VERSION ""

NS_ :

BS_:

BU_: FUSION ZONE_FR ZONE_RR

BO_ 513 ZFR_C5000_0: 32 ZONE_FR
 SG_ ZFR_CHASSIS_LiningWearFL_Sta : 7|1@0+ (1,0) [0|1] "" FUSION
 SG_ ZFR_CHASSIS_LiningWearFR_Sta : 6|1@0+ (1,0) [0|1] "" FUSION

BO_ 514 ZRR_C5000_0: 32 ZONE_RR
 SG_ ZRR_CHASSIS_LiningWearRR_Sta : 7|1@0+ (1,0) [0|1] "" FUSION
 SG_ ZRR_CHASSIS_LiningWearRL_Sta : 6|1@0+ (1,0) [0|1] "" FUSION

BO_ 515 ZFR_C100_0: 32 ZONE_FR
 SG_ ParkBrakeSW : 7|2@0+ (1,0) [0|3] "" FUSION

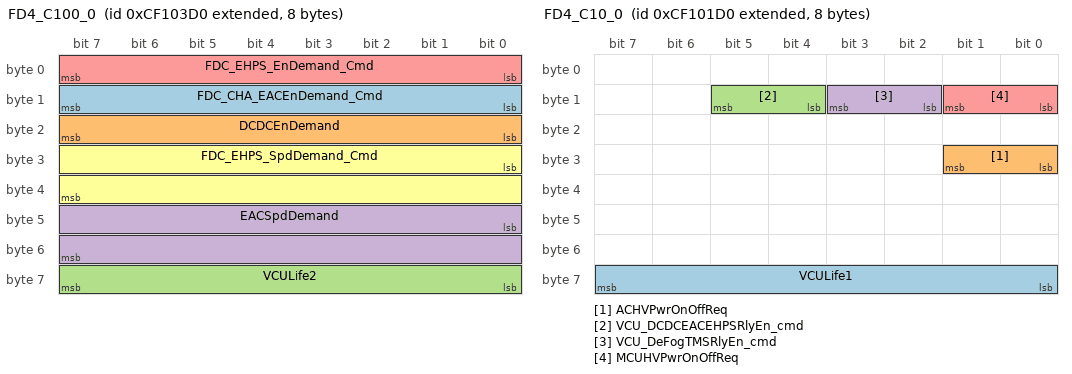
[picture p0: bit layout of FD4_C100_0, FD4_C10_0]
BO_ 2364605392 FD4_C100_0: 8 FUSION
 SG_ FDC_CHA_EACEnDemand_Cmd : 8|8@1+ (1,0) [0|255] "" ZONE_RR
 SG_ DCDCEnDemand : 16|8@1+ (1,0) [0|255] "" ZONE_RR
 SG_ VCULife2 : 56|8@1+ (1,0) [0|255] "" ZONE_RR
 SG_ EACSpdDemand : 40|16@1+ (0.5,-5000) [-5000|27767.5] "rpm" ZONE_RR
 SG_ FDC_EHPS_EnDemand_Cmd : 0|8@1+ (1,0) [0|255] "" ZONE_RR
 SG_ FDC_EHPS_SpdDemand_Cmd : 24|16@1+ (0.5,-5000) [-5000|5000] "rpm" ZONE_RR

BO_ 2566803180 ZRR_CE100_0: 8 ZONE_RR
 SG_ ZRR_BCM_AllDoor_Sta : 0|4@1+ (1,0) [0|15] "" FUSION

BO_ 517 ZFR_CE100_0: 32 ZONE_FR
 SG_ ZFR_BCM_Seatbelt_Sta : 7|1@0+ (1,0) [0|1] "" FUSION
 SG_ ZFR_BCM_Brake_Sta : 6|1@0+ (1,0) [0|1] "" FUSION
 SG_ ZFR_BCM_DVRSignalR_Sta : 5|1@0+ (1,0) [0|1] "" FUSION
 SG_ ZFR_BCM_DVRSignalL_Sta : 4|1@0+ (1,0) [0|1] "" FUSION
 SG_ ZFR_BCM_TurnBuzzer_Sta : 3|1@0+ (1,0) [0|1] "" FUSION
 SG_ ZFR_BCM_RBSDY_Sta : 2|1@0+ (1,0) [0|1] "" FUSION
 SG_ ZFR_BCM_LBSDY_Sta : 1|1@0+ (1,0) [0|1] "" FUSION
 SG_ ZFR_BCM_RBSDR_Sta : 0|1@0+ (1,0) [0|1] "" FUSION
 SG_ ZFR_BCM_LBSDR_Sta : 15|1@0+ (1,0) [0|1] "" FUSION
 SG_ ZFR_BCM_RFogLp_SW_Sta : 14|1@0+ (1,0) [0|1] "" FUSION
 SG_ ZFR_BCM_Washer_Sta : 13|1@0+ (1,0) [0|1] "" FUSION
 SG_ ZFR_BCM_WiperAS_Sta : 12|1@0+ (1,0) [0|1] "" FUSION
 SG_ ZFR_BCM_WiperL_Sta : 11|1@0+ (1,0) [0|1] "" FUSION
 SG_ ZFR_BCM_WiperH_Sta : 10|1@0+ (1,0) [0|1] "" FUSION
 SG_ ZFR_BCM_DVRMidDoor_Sta : 9|1@0+ (1,0) [0|1] "" FUSION
 SG_ ZFR_BCM_RFTurnLp_Sta : 8|1@0+ (1,0) [0|1] "" FUSION
 SG_ ZFR_BCM_LFTurnLp_Sta : 23|1@0+ (1,0) [0|1] "" FUSION
 SG_ ZFR_BCM_RDRL_Sta : 22|1@0+ (1,0) [0|1] "" FUSION
 SG_ ZFR_BCM_LDRL_Sta : 21|1@0+ (1,0) [0|1] "" FUSION
 SG_ ZFR_BCM_PLamp_Sta : 19|1@0+ (1,0) [0|1] "" FUSION
 SG_ ZFR_BCM_HBeam_Sta : 18|1@0+ (1,0) [0|1] "" FUSION
 SG_ ZFR_BCM_LBeam_Sta : 17|1@0+ (1,0) [0|1] "" FUSION
 SG_ ZFR_BCM_LightSensorV_Sta : 31|8@0+ (0.0196,0) [0|4.998] "V" FUSION
 SG_ ZFR_BCM_HBeamSW_Sta : 16|1@0+ (1,0) [0|1] "" FUSION
 SG_ ZFR_BCM_AutoLightSW_Sta : 39|1@0+ (1,0) [0|1] "" FUSION
 SG_ ZFR_BCM_PosLpSW_Sta : 38|1@0+ (1,0) [0|1] "" FUSION
 SG_ ZFR_BCM_HeadLpSW_Sta : 37|1@0+ (1,0) [0|1] "" FUSION
 SG_ ZFR_BCM_WiperHSW_Sta : 36|1@0+ (1,0) [0|1] "" FUSION
 SG_ ZFR_BCM_WiperLSW_Sta : 35|1@0+ (1,0) [0|1] "" FUSION
 SG_ ZFR_BCM_WasherSW_Sta : 34|1@0+ (1,0) [0|1] "" FUSION
 SG_ ZFR_BCM_HornSW_Sta : 33|1@0+ (1,0) [0|1] "" FUSION
 SG_ ZFR_BCM_RFTurnLpC_Sta : 47|8@0+ (0.025,0) [0|6.375] "A" FUSION
 SG_ ZFR_BCM_LFTurnLpC_Sta : 55|8@0+ (0.025,0) [0|6.375] "A" FUSION
 SG_ ZFR_BCM_BSD_Dimmer_Sta : 63|7@0+ (1,0) [0|127] "%" FUSION
 SG_ ZFR_BCM_BacklightDuty_Sta : 71|7@0+ (1,0) [0|127] "%" FUSION
 SG_ AirPressureFC2 : 79|8@0+ (8,0) [0|2008] "kPa" FUSION
 SG_ ZFR_BCM_DVRSignalReverse_Sta : 32|1@0+ (1,0) [0|1] "" FUSION

BO_ 518 ZRR_CE100_1: 32 ZONE_RR
 SG_ ZRR_BCM_EmSV_Sta : 7|1@0+ (1,0) [0|1] "" FUSION
 SG_ ZRR_BCM_MDoorAP_Sta : 6|1@0+ (1,0) [0|1] "" FUSION
 SG_ ZRR_BCM_FDoorAP_Sta : 5|1@0+ (1,0) [0|1] "" FUSION
 SG_ ZRR_BCM_MDCloseSV_Sta : 4|1@0+ (1,0) [0|1] "" FUSION
 SG_ ZRR_BCM_MDOpenSV_Sta : 3|1@0+ (1,0) [0|1] "" FUSION
 SG_ ZRR_BCM_FDCloseSV_Sta : 2|1@0+ (1,0) [0|1] "" FUSION
 SG_ ZRR_BCM_FDOpenSV_Sta : 1|1@0+ (1,0) [0|1] "" FUSION
 SG_ ZRR_BCM_ReverseBuz_Sta : 0|1@0+ (1,0) [0|1] "" FUSION
 SG_ ZRR_BCM_ReverseLp_Sta : 15|1@0+ (1,0) [0|1] "" FUSION
 SG_ ZRR_BCM_PLamp_Sta : 14|1@0+ (1,0) [0|1] "" FUSION
 SG_ ZRR_BCM_BrakeLp_Sta : 13|1@0+ (1,0) [0|1] "" FUSION
 SG_ ZRR_BCM_RFLamp_Sta : 12|1@0+ (1,0) [0|1] "" FUSION
 SG_ ZRR_BCM_TurnBuzzer_Sta : 11|1@0+ (1,0) [0|1] "" FUSION
 SG_ ZRR_BCM_RRTurnLpC_Sta : 23|8@0+ (0.025,0) [0|6.375] "A" FUSION
 SG_ ZRR_BCM_LRTurnLpC_Sta : 31|8@0+ (0.025,0) [0|6.375] "A" FUSION
 SG_ ZRR_BCM_RRTurnLp_Sta : 10|1@0+ (1,0) [0|1] "" FUSION
 SG_ ZRR_BCM_LRTurnLp_Sta : 9|1@0+ (1,0) [0|1] "" FUSION
 SG_ ZRR_BCM_CallingSW_Sta : 8|1@0+ (1,0) [0|1] "" FUSION
 SG_ ZRR_BCM_STOPSW2_Sta : 39|1@0+ (1,0) [0|1] "" FUSION
 SG_ ZRR_BCM_STOPSW_Sta : 38|1@0+ (1,0) [0|1] "" FUSION
 SG_ ZRR_BCM_SLTLp_Sta : 37|1@0+ (1,0) [0|1] "" FUSION
 SG_ ZRR_BCM_SRTLp_Sta : 36|1@0+ (1,0) [0|1] "" FUSION
 SG_ ZRR_BCM_SMKR_Sta : 35|1@0+ (1,0) [0|1] "" FUSION
 SG_ ZRR_BCM_SMKL_Sta : 34|1@0+ (1,0) [0|1] "" FUSION
 SG_ ZRR_BCM_RoomLpAmb_Sta : 33|1@0+ (1,0) [0|1] "" FUSION
 SG_ ZRR_BCM_StopLight_Sta : 32|1@0+ (1,0) [0|1] "" FUSION
 SG_ AirPressurePC3 : 47|8@0+ (8,0) [0|2000] "kPa" FUSION
 SG_ AirPressureRC1 : 55|8@0+ (8,0) [0|2008] "kPa" FUSION
 SG_ FDC_CHASSIS_VCUEACPress_Sta : 71|1@0+ (1,0) [0|1] "" FUSION
 SG_ ZRR_BCM_EmLight_Sta : 63|1@0+ (1,0) [0|1] "" FUSION

BO_ 522 zGW_CANRr1_C50_0: 32 ZONE_RR
 SG_ EAC_InvTemp_Sta : 0|8@1+ (1,-40) [-40|150] "degC" FUSION
 SG_ EHPS_InvTemp_Sta : 8|8@1+ (1,-40) [-40|150] "degC" FUSION
 SG_ DCDC_Temp_Sta : 16|8@1+ (1,-40) [-40|200] "degC" FUSION
 SG_ EAC_ErrLv_Sta : 24|3@1+ (1,0) [0|7] "" FUSION
 SG_ DCDC_OutVol_Sta : 32|16@1+ (0.1,0) [0|1000] "V" FUSION
 SG_ PDU_DCDCEACEHPSHVLoop_Sta : 27|2@1+ (1,0) [0|3] "" FUSION
 SG_ PDU_DCDCEACEHPSPreRly_Sta : 29|2@1+ (1,0) [0|3] "" FUSION
 SG_ PDU_SelfChk_Sta : 48|2@1+ (1,0) [0|3] "" FUSION
 SG_ PDU_MCUPreRly_Sta : 50|2@1+ (1,0) [0|3] "" FUSION
 SG_ PDU_MCUPosRly_Sta : 52|2@1+ (1,0) [0|3] "" FUSION
 SG_ PDU_MCUHVLoop_Sta : 54|2@1+ (1,0) [0|3] "" FUSION
 SG_ PDU_ACRly_Sta : 56|2@1+ (1,0) [0|3] "" FUSION
 SG_ PDU_DeFogTMSRly_Sta : 58|2@1+ (1,0) [0|3] "" FUSION
 SG_ PDU_DCDCEACEHPSRly_Sta : 60|2@1+ (1,0) [0|3] "" FUSION
 SG_ PDU_HVIL_Sta : 62|2@1+ (1,0) [0|3] "" FUSION
 SG_ EHPS_ErrLv_Sta : 64|3@1+ (1,0) [0|7] "" FUSION
 SG_ EHPS_En_Sta : 67|2@1+ (1,0) [0|3] "" FUSION
 SG_ EAC_En_Sta : 69|2@1+ (1,0) [0|3] "" FUSION
 SG_ DCDC_ErrLv_Sta : 72|3@1+ (1,0) [0|7] "" FUSION
 SG_ DCDC_En_Sta : 75|2@1+ (1,0) [0|3] "" FUSION
 SG_ EAC_LifeSig_Sta : 80|8@1+ (1,0) [0|255] "" FUSION
 SG_ DCDC_LifeSig_Sta : 88|8@1+ (1,0) [0|255] "" FUSION
 SG_ EHPS_MotorSpd_Sta : 96|16@1+ (0.5,-5000) [-5000|5000] "rpm" FUSION
 SG_ EHPS_LifeSig_Sta : 112|8@1+ (1,0) [0|255] "" FUSION
 SG_ PDU_LifeSig_Sta : 120|8@1+ (1,0) [0|255] "" FUSION

BO_ 2364604880 FD4_C10_0: 8 FUSION
 SG_ VCULife1 : 56|8@1+ (1,0) [0|255] "" ZONE_RR
 SG_ ACHVPwrOnOffReq : 24|2@1+ (1,0) [0|3] "" ZONE_RR
 SG_ VCU_DCDCEACEHPSRlyEn_cmd : 12|2@1+ (1,0) [0|3] "" ZONE_RR
 SG_ VCU_DeFogTMSRlyEn_cmd : 10|2@1+ (1,0) [0|3] "" ZONE_RR
 SG_ MCUHVPwrOnOffReq : 8|2@1+ (1,0) [0|3] "" ZONE_RR

BO_ 521 FD4_CE100_0: 32 FUSION
 SG_ FDC_BCM_EmSV_Cmd : 6|1@0+ (1,0) [0|1] "" ZONE_RR
 SG_ FDC_BCM_MDCloseSV_Cmd : 5|1@0+ (1,0) [0|1] "" ZONE_RR
 SG_ FDC_BCM_MDOpenSV_Cmd : 4|1@0+ (1,0) [0|1] "" ZONE_RR
 SG_ FDC_BCM_FDCloseSV_Cmd : 3|1@0+ (1,0) [0|1] "" ZONE_RR
 SG_ FDC_BCM_FDOpenSV_Cmd : 2|1@0+ (1,0) [0|1] "" ZONE_RR
 SG_ FDC_BCM_OutDoorOpenSW_Sta : 1|2@0+ (1,0) [0|3] "" ZONE_RR,ZONE_FR
 SG_ FDC_BCM_EmExitSW_Sta : 9|1@0+ (1,0) [0|1] "" ZONE_FR
 SG_ FDC_BCM_InnerBuzzer_Cmd : 8|1@0+ (1,0) [0|1] "" ZONE_FR
 SG_ FDC_BCM_InnerBuzzerMode_Sta : 23|3@0+ (1,0) [0|7] "" ZONE_FR
 SG_ FDC_BCM_CallBell_Cmd : 20|1@0+ (1,0) [0|1] "" ZONE_FR
 SG_ FDC_BCM_InnerCallBell_Cmd : 19|1@0+ (1,0) [0|1] "" ZONE_FR
 SG_ FDC_BCM_STOPBALL_Cmd : 18|1@0+ (1,0) [0|1] "" ZONE_FR
 SG_ FDC_BCM_TurnLpPattern_Sta : 17|2@0+ (1,0) [0|3] "" ZONE_FR
 SG_ FDC_BCM_RFLamp_Cmd : 31|1@0+ (1,0) [0|1] "" ZONE_RR
 SG_ FDC_BCM_Brake_Cmd : 30|1@0+ (1,0) [0|1] "" ZONE_RR,ZONE_FR
 SG_ FDC_BCM_SLTLp_Cmd : 29|1@0+ (1,0) [0|1] "" ZONE_RR
 SG_ FDC_BCM_SRTLp_Cmd : 28|1@0+ (1,0) [0|1] "" ZONE_RR
 SG_ FDC_BCM_SMKR_Cmd : 27|1@0+ (1,0) [0|1] "" ZONE_RR
 SG_ FDC_BCM_SMKL_Cmd : 26|1@0+ (1,0) [0|1] "" ZONE_RR
 SG_ FDC_BCM_RoomLpAmb_Cmd : 25|1@0+ (1,0) [0|1] "" ZONE_RR,ZONE_FR
 SG_ FDC_BCM_Stop_IND_Cmd : 24|1@0+ (1,0) [0|1] "" ZONE_RR,ZONE_FR
 SG_ FDC_BCM_BSD_Buzzer_Cmd : 39|1@0+ (1,0) [0|1] "" ZONE_RR,ZONE_FR
 SG_ FDC_BCM_RBSDY_Cmd : 38|1@0+ (1,0) [0|1] "" ZONE_FR
 SG_ FDC_BCM_RBSDR_Cmd : 37|1@0+ (1,0) [0|1] "" ZONE_FR
 SG_ FDC_BCM_LBSDY_Cmd : 36|1@0+ (1,0) [0|1] "" ZONE_FR
 SG_ FDC_BCM_LBSDR_Cmd : 35|1@0+ (1,0) [0|1] "" ZONE_FR
 SG_ FDC_BCM_Washer_Cmd : 34|1@0+ (1,0) [0|1] "" ZONE_FR
 SG_ FDC_BCM_WiperL_Cmd : 33|1@0+ (1,0) [0|1] "" ZONE_FR
 SG_ FDC_BCM_WiperH_Cmd : 32|1@0+ (1,0) [0|1] "" ZONE_FR
 SG_ FDC_BCM_RGear_Sta : 47|1@0+ (1,0) [0|1] "" ZONE_RR,ZONE_FR
 SG_ FDC_BCM_RDoor_Sta : 46|1@0+ (1,0) [0|1] "" ZONE_RR,ZONE_FR
 SG_ FDC_BCM_FDoor_Sta : 45|1@0+ (1,0) [0|1] "" ZONE_RR,ZONE_FR
 SG_ FDC_BCM_MDoor_Sta : 44|1@0+ (1,0) [0|1] "" ZONE_RR,ZONE_FR
 SG_ FDC_BCM_RDRL_Cmd : 43|1@0+ (1,0) [0|1] "" ZONE_FR
 SG_ FDC_BCM_LDRL_Cmd : 42|1@0+ (1,0) [0|1] "" ZONE_FR
 SG_ FDC_BCM_PLamp_Cmd : 41|1@0+ (1,0) [0|1] "" ZONE_RR,ZONE_FR
 SG_ FDC_BCM_HBeam_Cmd : 40|1@0+ (1,0) [0|1] "" ZONE_FR
 SG_ FDC_BCM_LBeam_Cmd : 55|1@0+ (1,0) [0|1] "" ZONE_FR
 SG_ FDC_BCM_LTurnLp_Cmd : 54|1@0+ (1,0) [0|1] "" ZONE_RR,ZONE_FR
 SG_ FDC_BCM_RTurnLp_Cmd : 53|1@0+ (1,0) [0|1] "" ZONE_RR,ZONE_FR
 SG_ FDC_BCM_DVRSignalR_Cmd : 51|1@0+ (1,0) [0|1] "" ZONE_FR
 SG_ FDC_BCM_DVRSignalL_Cmd : 52|1@0+ (1,0) [0|1] "" ZONE_FR
 SG_ VCUKeyStatus : 11|2@0+ (1,0) [0|3] "" ZONE_RR,ZONE_FR

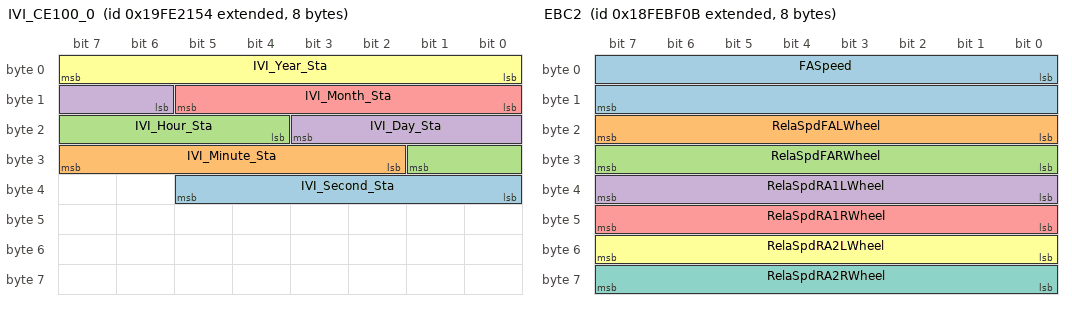
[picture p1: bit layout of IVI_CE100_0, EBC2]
BO_ 2583568724 IVI_CE100_0: 8 FUSION
 SG_ IVI_Second_Sta : 32|6@1+ (1,0) [0|60] "second" ZONE_RR,ZONE_FR
 SG_ IVI_Minute_Sta : 26|6@1+ (1,0) [0|60] "minute" ZONE_RR,ZONE_FR
 SG_ IVI_Hour_Sta : 20|6@1+ (1,0) [0|23] "hour" ZONE_RR,ZONE_FR
 SG_ IVI_Day_Sta : 14|6@1+ (1,0) [0|31] "day" ZONE_RR,ZONE_FR
 SG_ IVI_Month_Sta : 8|6@1+ (1,0) [0|13] "month" ZONE_RR,ZONE_FR
 SG_ IVI_Year_Sta : 0|8@1+ (1,2000) [2000|2127] "year" ZONE_RR,ZONE_FR

BO_ 2566831883 EBC2: 8 FUSION
 SG_ FASpeed : 0|16@1+ (0.00390625,0) [0|255.99609375] "km/h" ZONE_RR,ZONE_FR
 SG_ RelaSpdFALWheel : 16|8@1+ (0.0625,-7.8125) [-7.8125|7.8125] "km/h" Vector__XXX
 SG_ RelaSpdFARWheel : 24|8@1+ (0.0625,-7.8125) [-7.8125|7.8125] "km/h" Vector__XXX
 SG_ RelaSpdRA1LWheel : 32|8@1+ (0.0625,-7.8125) [-7.8125|7.8125] "km/h" Vector__XXX
 SG_ RelaSpdRA1RWheel : 40|8@1+ (0.0625,-7.8125) [-7.8125|7.8125] "km/h" Vector__XXX
 SG_ RelaSpdRA2LWheel : 48|8@1+ (0.0625,-7.8125) [-7.8125|7.8125] "km/h" Vector__XXX
 SG_ RelaSpdRA2RWheel : 56|8@1+ (0.0625,-7.8125) [-7.8125|7.8125] "km/h" Vector__XXX

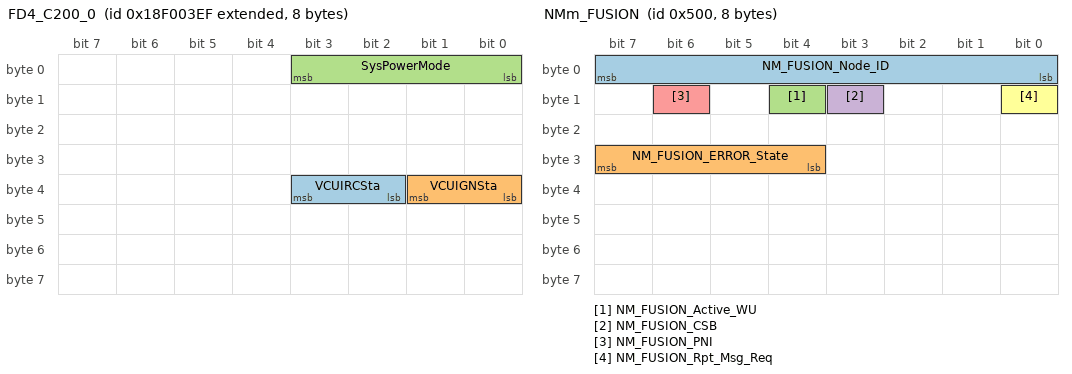
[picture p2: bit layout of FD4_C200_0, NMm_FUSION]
BO_ 2565866479 FD4_C200_0: 8 FUSION
 SG_ VCUIRCSta : 34|2@1+ (1,0) [0|3] "" ZONE_RR,ZONE_FR
 SG_ VCUIGNSta : 32|2@1+ (1,0) [0|3] "" ZONE_RR,ZONE_FR
 SG_ SysPowerMode : 0|4@1+ (1,0) [0|15] "" ZONE_RR,ZONE_FR

BO_ 2000 DiagFuncReqFT: 8 FUSION
 SG_ DiagFuncReqFT : 7|64@0+ (1,0) [0|1.8446744073709551E19] "" ZONE_RR,ZONE_FR

BO_ 1764 DiagPhysReqToZONE_RR: 64 FUSION
 SG_ DiagPhysReqToZONE_RR : 7|64@0+ (1,0) [0|1.8446744073709551E19] "" ZONE_RR

BO_ 1636 DiagRespFromZONE_RR: 64 ZONE_RR
 SG_ DiagRespFromZONE_RR : 7|64@0+ (1,0) [0|1.8446744073709551E19] "" FUSION

BO_ 1668 DiagPhysReqToZONE_FR: 64 FUSION
 SG_ DiagPhysReqToZONE_FR : 7|64@0+ (1,0) [0|1.8446744073709551E19] "" ZONE_FR

BO_ 1540 DiagRespFromZONE_FR: 64 ZONE_FR
 SG_ DiagRespFromZONE_FR : 7|64@0+ (1,0) [0|1.8446744073709551E19] "" FUSION

BO_ 528 FD4_CE100_1: 32 FUSION
 SG_ FDC_BCM_RRoomLp_Cmd : 7|7@0+ (1,0) [0|127] "%" ZONE_RR
 SG_ FDC_BCM_FRoomLp_Cmd : 39|7@0+ (1,0) [0|127] "%" ZONE_RR
 SG_ FDC_BCM_MRoomLp_Cmd : 47|7@0+ (1,0) [0|127] "%" ZONE_RR
 SG_ FDC_THCM_CoolFanReq_Cmd : 15|8@0+ (0.5,0) [0|100] "%" ZONE_RR

BO_ 1280 NMm_FUSION: 8 FUSION
 SG_ NM_FUSION_Node_ID : 7|8@0+ (1,0) [0|255] "" ZONE_RR,ZONE_FR
 SG_ NM_FUSION_ERROR_State : 31|4@0+ (1,0) [0|15] "" ZONE_RR,ZONE_FR
 SG_ NM_FUSION_Active_WU : 12|1@0+ (1,0) [0|1] "" ZONE_RR,ZONE_FR
 SG_ NM_FUSION_CSB : 11|1@0+ (1,0) [0|1] "" ZONE_RR,ZONE_FR
 SG_ NM_FUSION_PNI : 14|1@0+ (1,0) [0|1] "" ZONE_RR,ZONE_FR
 SG_ NM_FUSION_Rpt_Msg_Req : 8|1@0+ (1,0) [0|1] "" ZONE_RR,ZONE_FR

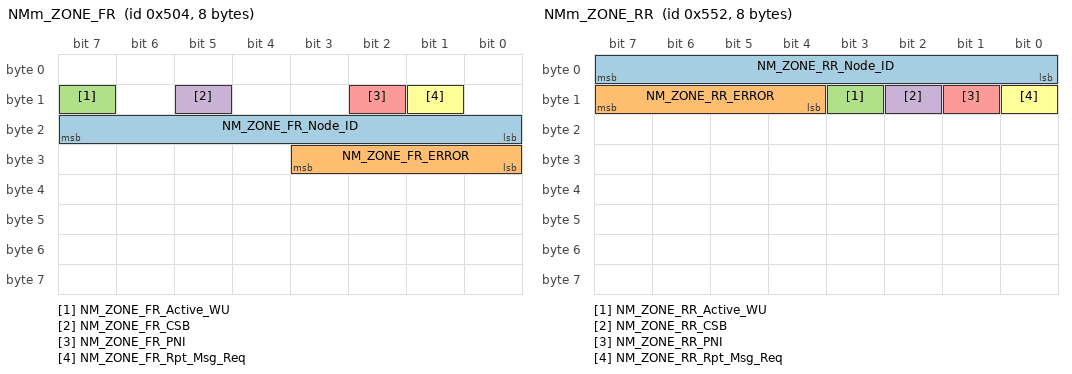
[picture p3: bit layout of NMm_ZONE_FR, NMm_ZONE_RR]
BO_ 1284 NMm_ZONE_FR: 8 ZONE_FR
 SG_ NM_ZONE_FR_Node_ID : 23|8@0+ (1,0) [0|255] "" FUSION
 SG_ NM_ZONE_FR_ERROR : 27|4@0+ (1,0) [0|15] "" FUSION
 SG_ NM_ZONE_FR_Active_WU : 15|1@0+ (1,0) [0|1] "" FUSION
 SG_ NM_ZONE_FR_CSB : 13|1@0+ (1,0) [0|1] "" FUSION
 SG_ NM_ZONE_FR_PNI : 10|1@0+ (1,0) [0|1] "" FUSION
 SG_ NM_ZONE_FR_Rpt_Msg_Req : 9|1@0+ (1,0) [0|1] "" FUSION

BO_ 1362 NMm_ZONE_RR: 8 ZONE_RR
 SG_ NM_ZONE_RR_Node_ID : 7|8@0+ (1,0) [0|255] "" FUSION
 SG_ NM_ZONE_RR_ERROR : 15|4@0+ (1,0) [0|15] "" FUSION
 SG_ NM_ZONE_RR_Active_WU : 11|1@0+ (1,0) [0|1] "" FUSION
 SG_ NM_ZONE_RR_CSB : 10|1@0+ (1,0) [0|1] "" FUSION
 SG_ NM_ZONE_RR_PNI : 9|1@0+ (1,0) [0|1] "" FUSION
 SG_ NM_ZONE_RR_Rpt_Msg_Req : 8|1@0+ (1,0) [0|1] "" FUSION

CM_ BO_ 2566803180 "FPT1_104.4_Draft，DC";
CM_ BO_ 2364604880 "FPT1_104.4_Draft，VCU_PDU_Demand_1";
CM_ BO_ 2565866479 "FPT1_104.4_Draft，VCU3";
CM_ SG_ 513 ZFR_CHASSIS_LiningWearFL_Sta "Status of FL Brake Lining";
CM_ SG_ 513 ZFR_CHASSIS_LiningWearFR_Sta "Status of FR Brake Lining";
CM_ SG_ 514 ZRR_CHASSIS_LiningWearRR_Sta "Status of RR Brake Lining";
CM_ SG_ 514 ZRR_CHASSIS_LiningWearRL_Sta "Status of RL Brake Lining";
CM_ SG_ 515 ParkBrakeSW "Parking brake switch(SPN70)";
CM_ SG_ 2364605392 FDC_CHA_EACEnDemand_Cmd "EAC enables control";
CM_ SG_ 2364605392 DCDCEnDemand "DCDC使能控制
DCDC enables control";
CM_ SG_ 2364605392 VCULife2 "VCU 生命信號
VCU Life signal";
CM_ SG_ 2364605392 EACSpdDemand "EAC電機轉速指令
EAC motor speed Demand";
CM_ SG_ 2364605392 FDC_EHPS_EnDemand_Cmd "EHPS Enable Demand";
CM_ SG_ 2364605392 FDC_EHPS_SpdDemand_Cmd "EHPS Speed Demand";
CM_ SG_ 2566803180 ZRR_BCM_AllDoor_Sta "Door Control-Status of doors(SPN 1821)
   0000b At least 1 door is open;
   0001b Closing last door;
   0010b All doors closed;
   0011b ... 1101Not defined;";
CM_ SG_ 517 ZFR_BCM_Seatbelt_Sta "Seat belt";
CM_ SG_ 517 ZFR_BCM_Brake_Sta "Output Brake Status of Zone FR";
CM_ SG_ 517 ZFR_BCM_DVRSignalR_Sta "Output DVRSignalR Status of Zone FR";
CM_ SG_ 517 ZFR_BCM_DVRSignalL_Sta "Output DVRSignalL Status of Zone FR";
CM_ SG_ 517 ZFR_BCM_TurnBuzzer_Sta "TurnBuzzer Status of Zone FR";
CM_ SG_ 517 ZFR_BCM_RBSDY_Sta "Output RBSDY Status of Zone FR";
CM_ SG_ 517 ZFR_BCM_LBSDY_Sta "Output LBSDY Status of Zone FR";
CM_ SG_ 517 ZFR_BCM_RBSDR_Sta "Output RBSDR Status of Zone FR";
CM_ SG_ 517 ZFR_BCM_LBSDR_Sta "Output LBSDR Status of Zone FR";
CM_ SG_ 517 ZFR_BCM_RFogLp_SW_Sta "Rear Fog Lamp SW";
CM_ SG_ 517 ZFR_BCM_Washer_Sta "Wiper Washer Status of Zone FR";
CM_ SG_ 517 ZFR_BCM_WiperAS_Sta "Front Wiper Park Signal";
CM_ SG_ 517 ZFR_BCM_WiperL_Sta "Wiper Low  Status of Zone FR";
CM_ SG_ 517 ZFR_BCM_WiperH_Sta "Wiper Hight Status of Zone FR";
CM_ SG_ 517 ZFR_BCM_DVRMidDoor_Sta "Output DVRMidDoor Status of Zone FR";
CM_ SG_ 517 ZFR_BCM_RFTurnLp_Sta "Right Front Turn Lamp Status of Zone FR";
CM_ SG_ 517 ZFR_BCM_LFTurnLp_Sta "Left Front Turn Lamp Status of Zone FR";
CM_ SG_ 517 ZFR_BCM_RDRL_Sta "Right DRL Lamp Status of Zone FR";
CM_ SG_ 517 ZFR_BCM_LDRL_Sta "Left DRL Lamp Status of Zone FR";
CM_ SG_ 517 ZFR_BCM_PLamp_Sta "Position Lamp Status of Zone FR";
CM_ SG_ 517 ZFR_BCM_HBeam_Sta "High Beam Lamp Status of Zone FR";
CM_ SG_ 517 ZFR_BCM_LBeam_Sta "Low Beam Lamp Status of Zone FR";
CM_ SG_ 517 ZFR_BCM_LightSensorV_Sta "Light Sensor 電壓";
CM_ SG_ 517 ZFR_BCM_HBeamSW_Sta "High Beam SW";
CM_ SG_ 517 ZFR_BCM_AutoLightSW_Sta "Auto Light Switch";
CM_ SG_ 517 ZFR_BCM_PosLpSW_Sta "Position Lamp SW";
CM_ SG_ 517 ZFR_BCM_HeadLpSW_Sta "Low Beam SW";
CM_ SG_ 517 ZFR_BCM_WiperHSW_Sta "Front Wiper Low SW";
CM_ SG_ 517 ZFR_BCM_WiperLSW_Sta "Front Wiper Low SW";
CM_ SG_ 517 ZFR_BCM_WasherSW_Sta "Front Washer SW";
CM_ SG_ 517 ZFR_BCM_HornSW_Sta "HornSW Status of Zone FR";
CM_ SG_ 517 ZFR_BCM_RFTurnLpC_Sta "Right FrontTurn Lamp Current of Zone FR";
CM_ SG_ 517 ZFR_BCM_LFTurnLpC_Sta "Left FrontTurn Lamp Current of Zone FR";
CM_ SG_ 517 ZFR_BCM_BSD_Dimmer_Sta "BSD Dimmer Status of Zone FR";
CM_ SG_ 517 ZFR_BCM_BacklightDuty_Sta "Backlight Duty Status of Zone FR";
CM_ SG_ 517 AirPressureFC2 "The pneumatic pressure in the secondary service brake circuit or reservoir, supplying the front axle";
CM_ SG_ 517 ZFR_BCM_DVRSignalReverse_Sta "Output DVRSignalReverse Status of Zone FR";
CM_ SG_ 518 ZRR_BCM_EmSV_Sta "Emergency Solenoid Valve Status of Zone RR";
CM_ SG_ 518 ZRR_BCM_MDoorAP_Sta "Middle Door Anti-pinch Status of Zone RR";
CM_ SG_ 518 ZRR_BCM_FDoorAP_Sta "Front Door Anti-pinch Status of Zone RR";
CM_ SG_ 518 ZRR_BCM_MDCloseSV_Sta "Middle Door CLose Solenoid Valve Status of Zone RR";
CM_ SG_ 518 ZRR_BCM_MDOpenSV_Sta "Middle Door Open Solenoid Valve Status of Zone RR";
CM_ SG_ 518 ZRR_BCM_FDOpenSV_Sta "Front Door Open Solenoid Valve Status of Zone RR";
CM_ SG_ 518 ZRR_BCM_ReverseBuz_Sta "Reverse_Buzzer Status of Zone RR";
CM_ SG_ 518 ZRR_BCM_ReverseLp_Sta "Reverse Lamp Status of Zone RR";
CM_ SG_ 518 ZRR_BCM_PLamp_Sta "Rear Position Lamp Status of Zone RR";
CM_ SG_ 518 ZRR_BCM_BrakeLp_Sta "Brake Lamp Status of Zone RR";
CM_ SG_ 518 ZRR_BCM_TurnBuzzer_Sta "Turn Buzzer Status of Zone RR";
CM_ SG_ 518 ZRR_BCM_LRTurnLpC_Sta "Left Rear Turn Lamp Current of Zone RR";
CM_ SG_ 518 ZRR_BCM_RRTurnLp_Sta "Right Rear Turn Lamp Status of Zone RR";
CM_ SG_ 518 ZRR_BCM_CallingSW_Sta "Calling_Switch  Status of Zone RR";
CM_ SG_ 518 ZRR_BCM_STOPSW_Sta "Stop Switch Status of Zone RR";
CM_ SG_ 518 ZRR_BCM_SLTLp_Sta "Support  Left Turn Lamp Status of Zone RR";
CM_ SG_ 518 ZRR_BCM_SRTLp_Sta "Support  Right Turn Lamp Status of Zone RR";
CM_ SG_ 518 ZRR_BCM_SMKR_Sta "Right Side Maek Lamp Status of Zone RR";
CM_ SG_ 518 ZRR_BCM_SMKL_Sta "Left Side Maek Lamp Status of Zone RR";
CM_ SG_ 518 ZRR_BCM_RoomLpAmb_Sta "Ambient Lamp Status of Zone RR";
CM_ SG_ 518 ZRR_BCM_StopLight_Sta "Zone Rr Stop light status";
CM_ SG_ 518 AirPressurePC3 "The pneumatic pressure in the circuit or reservoir for the parking brake";
CM_ SG_ 518 AirPressureRC1 "The pneumatic pressure in the primary service brake circuit or reservoir, supplying the rear axle";
CM_ SG_ 518 FDC_CHASSIS_VCUEACPress_Sta "FDC_CHASSIS_VCUEACPress_Sta";
CM_ SG_ 518 ZRR_BCM_EmLight_Sta " Emergency Light Status  of Zone_RR BCM";
CM_ SG_ 522 EAC_InvTemp_Sta "EAC溫度
The EAC  temperature";
CM_ SG_ 522 EHPS_InvTemp_Sta "EHPS溫度
The EHPS temperature";
CM_ SG_ 522 DCDC_Temp_Sta "DCDC溫度
DCDC temperature";
CM_ SG_ 522 EAC_ErrLv_Sta "EAC故障等級
EAC fault level";
CM_ SG_ 522 DCDC_OutVol_Sta "DCDC輸出電壓
DCDC output voltage";
CM_ SG_ 522 PDU_DCDCEACEHPSHVLoop_Sta "DCDC/EAC/EHPS高壓迴路狀態
DCDC/EAC/EHPS HV Loop Status";
CM_ SG_ 522 PDU_DCDCEACEHPSPreRly_Sta "DCDC/EAC/EHPS預充接觸器狀態
DCDC/EAC/EHPS Pre Rly Status";
CM_ SG_ 522 PDU_SelfChk_Sta "PDU自檢狀態
PDU Selfcheck Status";
CM_ SG_ 522 PDU_MCUPreRly_Sta "MCU預充接觸器狀態
MCU Pre Rly Status";
CM_ SG_ 522 PDU_MCUPosRly_Sta "MCU主接觸器狀態
MCU Pos Rly Status";
CM_ SG_ 522 PDU_MCUHVLoop_Sta "MCU高壓回路狀態
MCU HV Loop Status";
CM_ SG_ 522 PDU_ACRly_Sta "空調接觸器狀態
AC Rly Status";
CM_ SG_ 522 PDU_DeFogTMSRly_Sta "DeFog/TMS Relay Enable Status";
CM_ SG_ 522 PDU_DCDCEACEHPSRly_Sta "DCDC/EAC/EHPS Relay Enable  Status";
CM_ SG_ 522 PDU_HVIL_Sta "高壓互鎖狀態
HVIL_status";
CM_ SG_ 522 EHPS_ErrLv_Sta "EHPS故障等級
EHPS fault level";
CM_ SG_ 522 EHPS_En_Sta "EHPS使能狀態
EHPS enable state";
CM_ SG_ 522 EAC_En_Sta "EAC使能狀態
EAC enables the state";
CM_ SG_ 522 DCDC_ErrLv_Sta "DCDC故障等級
DCDC fault level";
CM_ SG_ 522 DCDC_En_Sta "DCDC狀態
DCDC state";
CM_ SG_ 522 EAC_LifeSig_Sta "EAC生命信號
EAC Life signal";
CM_ SG_ 522 DCDC_LifeSig_Sta "DCDC控制器生命訊號
DCDC Life signal";
CM_ SG_ 522 EHPS_MotorSpd_Sta "EHPS電機轉速
EHPS motor speed";
CM_ SG_ 522 EHPS_LifeSig_Sta "EHPS生命信號
EHPS Life signal";
CM_ SG_ 522 PDU_LifeSig_Sta "PDU生命訊號
PDU Life Signal";
CM_ SG_ 2364604880 VCULife1 "VCU生命信號
VCU vital signs";
CM_ SG_ 2364604880 ACHVPwrOnOffReq "AC高壓回路上下電請求
AC_HV_PowerOn/Off_Request
(K2&K8)";
CM_ SG_ 2364604880 VCU_DCDCEACEHPSRlyEn_cmd "DCDC/EAC/EHPS Relay enable command";
CM_ SG_ 2364604880 VCU_DeFogTMSRlyEn_cmd "DeFog/TMS Relay enable command";
CM_ SG_ 2364604880 MCUHVPwrOnOffReq "MCU高壓回路上下電請求
MCU_HV_PowerOn/Off_Request
(K1&K7)";
CM_ SG_ 521 FDC_BCM_EmSV_Cmd "緊急電磁閥做動狀態
0=Door Can_Open ,1=Door Can not Open";
CM_ SG_ 521 FDC_BCM_MDCloseSV_Cmd "後門關閉電磁閥做動狀態";
CM_ SG_ 521 FDC_BCM_MDOpenSV_Cmd "後門開啟電磁閥做動狀態";
CM_ SG_ 521 FDC_BCM_FDCloseSV_Cmd "前門關閉電磁閥做動狀態";
CM_ SG_ 521 FDC_BCM_FDOpenSV_Cmd "Front Door OpenSV Command of FDC";
CM_ SG_ 521 FDC_BCM_OutDoorOpenSW_Sta "外部車門開啟開關狀態";
CM_ SG_ 521 FDC_BCM_EmExitSW_Sta "FDC_BCM_EmExitSW_Sta";
CM_ SG_ 521 FDC_BCM_InnerBuzzer_Cmd "InnerBuzzer Command of FDC";
CM_ SG_ 521 FDC_BCM_InnerBuzzerMode_Sta "Inner Buzzer Mode ";
CM_ SG_ 521 FDC_BCM_CallBell_Cmd "CallBell Command of FDC";
CM_ SG_ 521 FDC_BCM_InnerCallBell_Cmd "InnerCallBell Command of FDC";
CM_ SG_ 521 FDC_BCM_STOPBALL_Cmd "下車鈴響鈴狀態";
CM_ SG_ 521 FDC_BCM_TurnLpPattern_Sta " Turn Lamp Pattern Status of FDC";
CM_ SG_ 521 FDC_BCM_RFLamp_Cmd "Rear Fog Indicator
後霧燈指示燈";
CM_ SG_ 521 FDC_BCM_Brake_Cmd "BCM Brake Lamp Command of FDC";
CM_ SG_ 521 FDC_BCM_SLTLp_Cmd "Suppout Turn Lamp Right";
CM_ SG_ 521 FDC_BCM_SRTLp_Cmd "Suppout Turn Lamp Left";
CM_ SG_ 521 FDC_BCM_SMKR_Cmd "右側方標示燈";
CM_ SG_ 521 FDC_BCM_SMKL_Cmd "左側方標示燈";
CM_ SG_ 521 FDC_BCM_RoomLpAmb_Cmd "Ambient Lamp Command of FDC";
CM_ SG_ 521 FDC_BCM_Stop_IND_Cmd "StopRequest";
CM_ SG_ 521 FDC_BCM_BSD_Buzzer_Cmd "BSD Buzzer Command of FDC";
CM_ SG_ 521 FDC_BCM_RBSDY_Cmd "Right BSD Yellow";
CM_ SG_ 521 FDC_BCM_RBSDR_Cmd "Right BSD Red";
CM_ SG_ 521 FDC_BCM_LBSDY_Cmd "Left BSD Yellow";
CM_ SG_ 521 FDC_BCM_LBSDR_Cmd "Left BSD Red";
CM_ SG_ 521 FDC_BCM_Washer_Cmd "Wiper Washer Command of FDC";
CM_ SG_ 521 FDC_BCM_WiperL_Cmd "Wiper Low speed Command of FDC";
CM_ SG_ 521 FDC_BCM_WiperH_Cmd "Wiper High speed Command of FDC";
CM_ SG_ 521 FDC_BCM_RGear_Sta "BCM RGear Status of FDC";
CM_ SG_ 521 FDC_BCM_RDoor_Sta "Rear Door_Sta Status of FDC";
CM_ SG_ 521 FDC_BCM_FDoor_Sta "Front Door Open Indicaor
前門開啟指示燈";
CM_ SG_ 521 FDC_BCM_MDoor_Sta "Middle Door Open Indicaor
中門開啟指示燈";
CM_ SG_ 521 FDC_BCM_RDRL_Cmd "右晝行燈狀態";
CM_ SG_ 521 FDC_BCM_LDRL_Cmd "左晝行燈狀態";
CM_ SG_ 521 FDC_BCM_PLamp_Cmd "Postion Lamp Indicator
小燈(位置燈)指示燈";
CM_ SG_ 521 FDC_BCM_HBeam_Cmd "Hi Beam Indicaotr
遠光燈指示燈";
CM_ SG_ 521 FDC_BCM_LBeam_Cmd "Low Beam Indicator
近光燈指示燈";
CM_ SG_ 521 FDC_BCM_LTurnLp_Cmd "Left Turn Indicator
左方向燈指示燈";
CM_ SG_ 521 FDC_BCM_RTurnLp_Cmd "Right Turn Indicator
右方向燈指示燈";
CM_ SG_ 521 FDC_BCM_DVRSignalR_Cmd "Turn Lamp Right Acitve";
CM_ SG_ 521 FDC_BCM_DVRSignalL_Cmd "Turn Lamp Left Acitve";
CM_ SG_ 521 VCUKeyStatus "VCU internal key status";
CM_ SG_ 2583568724 IVI_Second_Sta "IVI_GPS Satellite Time_Second";
CM_ SG_ 2583568724 IVI_Minute_Sta "IVI_GPS Satellite Time_Minute";
CM_ SG_ 2583568724 IVI_Hour_Sta "IVI_GPS Satellite Time_Hour";
CM_ SG_ 2583568724 IVI_Day_Sta "IVI_GPS Satellite Time_Day";
CM_ SG_ 2583568724 IVI_Month_Sta "IVI_GPS Satellite Time_Month";
CM_ SG_ 2583568724 IVI_Year_Sta "IVI_GPS Satellite Time_Year";
CM_ SG_ 2566831883 FASpeed "Front Axle Vehicle Speed(64256~65535=Error)";
CM_ SG_ 2566831883 RelaSpdFALWheel "The speed of the front axle, left wheel relative to the front axle speed, SPN 904.";
CM_ SG_ 2566831883 RelaSpdFARWheel "The speed of the front axle, right wheel relative to the front axle speed, SPN 904.";
CM_ SG_ 2566831883 RelaSpdRA1LWheel "The speed of the rear axle #1, left wheel relative to the front axle speed, SPN 904.";
CM_ SG_ 2566831883 RelaSpdRA1RWheel "The speed of the rear axle #1, right wheel relative to the front axle speed, SPN 904.";
CM_ SG_ 2566831883 RelaSpdRA2LWheel "The speed of the rear axle #2, left wheel relative to the front axle speed, SPN 904.";
CM_ SG_ 2566831883 RelaSpdRA2RWheel "The speed of the rear axle #2, right wheel relative to the front axle speed, SPN 904.";
CM_ SG_ 2565866479 VCUIRCSta "IRC relay status";
CM_ SG_ 2565866479 VCUIGNSta "IGN relay status";
CM_ SG_ 2565866479 SysPowerMode "HV system current power mode";
CM_ SG_ 2000 DiagFuncReqFT "Diagnostic Functional Request from Tester";
CM_ SG_ 1764 DiagPhysReqToZONE_RR "Diagnostic Physical Request to ZONE_RR";
CM_ SG_ 1636 DiagRespFromZONE_RR "Diagnostic Response from ZONE_RR";
CM_ SG_ 1668 DiagPhysReqToZONE_FR "Diagnostic Physical Request to ZONE_FR";
CM_ SG_ 1540 DiagRespFromZONE_FR "Diagnostic Response from ZONE_FR";
CM_ SG_ 528 FDC_BCM_RRoomLp_Cmd "Rear-Room-Lamp brightness Command of FD-BCM";
CM_ SG_ 528 FDC_BCM_FRoomLp_Cmd "Front-Room-Lamp brightness Command of FD-BCM";
CM_ SG_ 528 FDC_BCM_MRoomLp_Cmd "Mid-Room-Lamp brightness Command of FD-BCM";
CM_ SG_ 528 FDC_THCM_CoolFanReq_Cmd "Cooling fan duty cycle command";
CM_ SG_ 1280 NM_FUSION_Node_ID "Source Node Identifier";
CM_ SG_ 1280 NM_FUSION_ERROR_State "Defined Error states of the CAN Controller";
CM_ SG_ 1280 NM_FUSION_Active_WU "Active Wakeup Bit";
CM_ SG_ 1280 NM_FUSION_CSB "NM Coordinator Sleep Bit";
CM_ SG_ 1280 NM_FUSION_PNI "Partial Network Information Bit (PNI)";
CM_ SG_ 1280 NM_FUSION_Rpt_Msg_Req "Repeat Message Request";
CM_ SG_ 1284 NM_ZONE_FR_Node_ID "Source Node Identifier";
CM_ SG_ 1284 NM_ZONE_FR_ERROR "Defined Error states of the CAN Controller";
CM_ SG_ 1284 NM_ZONE_FR_Active_WU "Active Wakeup Bit";
CM_ SG_ 1284 NM_ZONE_FR_CSB "NM Coordinator Sleep Bit";
CM_ SG_ 1284 NM_ZONE_FR_PNI "Partial Network Information Bit (PNI)";
CM_ SG_ 1284 NM_ZONE_FR_Rpt_Msg_Req "Repeat Message Request";
CM_ SG_ 1362 NM_ZONE_RR_Node_ID "Source Node Identifier";
CM_ SG_ 1362 NM_ZONE_RR_ERROR "Defined Error states of the CAN Controller";
CM_ SG_ 1362 NM_ZONE_RR_Active_WU "Active Wakeup Bit";
CM_ SG_ 1362 NM_ZONE_RR_CSB "NM Coordinator Sleep Bit";
CM_ SG_ 1362 NM_ZONE_RR_PNI "Partial Network Information Bit (PNI)";
CM_ SG_ 1362 NM_ZONE_RR_Rpt_Msg_Req "Repeat Message Request";

BA_DEF_ SG_ "GenSigInvalidValue" HEX 0 0;
BA_DEF_ SG_ "GenSigStartValue" HEX 0 0;
BA_DEF_ SG_ "GenSigRoutingTimeoutValue_String" STRING ;
BA_DEF_ SG_ "GenSigRoutingTimeoutValue" HEX 0 0;
BA_DEF_ SG_ "GenSigSendType" ENUM "Cycle","OnWrite","OnWriteWithRepetition","OnChange","OnChangeWithRepetition","IfActive","IfActiveWithRepetition","NoSigSendType","vector_leerstring";
BA_DEF_ SG_ "SigType" ENUM "Default","Range","RangeSigned","ASCII","Discrete","Control","ReferencePGN","DTC","StringDelimiter","StringLength","StringLengthControl","MessageCounter","MessageChecksum";
BA_DEF_ SG_ "GenSigILSupport" ENUM "No","Yes";
BA_DEF_ BU_ "NodeLayerModules" STRING ;
BA_DEF_ BU_ "NmCAN" INT 1 2;
BA_DEF_ BU_ "ILUsed" ENUM "No","Yes";
BA_DEF_ BU_ "CANFD_CANFD_Gateway" ENUM "Yes","No";
BA_DEF_ BU_ "CAN_CANFD_Gateway" ENUM "Yes","No";
BA_DEF_ BU_ "CANFD_LIN_Gateway" ENUM "Yes","No";
BA_DEF_ BU_ "CAN_CAN_Gateway" ENUM "Yes","No";
BA_DEF_ "NmType" STRING ;
BA_DEF_ "VersionYear" INT 2010 2999;
BA_DEF_ "ProtocolType" STRING ;
BA_DEF_ "NmMessageCount" INT 0 255;
BA_DEF_ "NmBaseAddress" HEX 1280 1407;
BA_DEF_ "DBName" STRING ;
BA_DEF_ "BusType" STRING ;
BA_DEF_ "Baudrate" INT 0 1000000;
BA_DEF_ "Datarate" INT 0 2000000;
BA_DEF_ BO_ "GenMsgSendType" ENUM "Cycle","NoMsgSendType","IfActive","Event","CA","CE";
BA_DEF_ BO_ "GenMsgNrOfRepetition" INT 0 0;
BA_DEF_ BO_ "GenMsgILSupport" ENUM "No","Yes";
BA_DEF_ BO_ "GenMsgCycleTime" INT 0 0;
BA_DEF_ BO_ "VFrameFormat" ENUM "StandardCAN","ExtendedCAN","reserved","reserved","reserved","reserved","reserved","reserved","reserved","reserved","reserved","reserved","reserved","reserved","StandardCAN_FD","ExtendedCAN_FD";
BA_DEF_ BO_ "DoIPLogicalAddress" STRING ;
BA_DEF_ BO_ "GenMsgRequestable" INT 0 0;
BA_DEF_ BO_ "CANFD_BRS" ENUM "0","1";
BA_DEF_DEF_ "GenSigInvalidValue" 0;
BA_DEF_DEF_ "GenSigStartValue" 0;
BA_DEF_DEF_ "GenSigRoutingTimeoutValue_String" "";
BA_DEF_DEF_ "GenSigRoutingTimeoutValue" 0;
BA_DEF_DEF_ "GenSigSendType" "Cycle";
BA_DEF_DEF_ "SigType" "Default";
BA_DEF_DEF_ "GenSigILSupport" "Yes";
BA_DEF_DEF_ "NodeLayerModules" "CANoeILNLVector.dll";
BA_DEF_DEF_ "NmCAN" 2;
BA_DEF_DEF_ "ILUsed" "Yes";
BA_DEF_DEF_ "CANFD_CANFD_Gateway" "No";
BA_DEF_DEF_ "CAN_CANFD_Gateway" "No";
BA_DEF_DEF_ "CANFD_LIN_Gateway" "No";
BA_DEF_DEF_ "CAN_CAN_Gateway" "No";
BA_DEF_DEF_ "NmType" "AUTOSAR";
BA_DEF_DEF_ "VersionYear" 2024;
BA_DEF_DEF_ "ProtocolType" "CAN";
BA_DEF_DEF_ "NmMessageCount" 128;
BA_DEF_DEF_ "NmBaseAddress" 1280;
BA_DEF_DEF_ "DBName" "";
BA_DEF_DEF_ "BusType" "CAN";
BA_DEF_DEF_ "Baudrate" 500000;
BA_DEF_DEF_ "Datarate" 2000000;
BA_DEF_DEF_ "GenMsgSendType" "Cycle";
BA_DEF_DEF_ "GenMsgNrOfRepetition" 0;
BA_DEF_DEF_ "GenMsgILSupport" "Yes";
BA_DEF_DEF_ "GenMsgCycleTime" 100;
BA_DEF_DEF_ "VFrameFormat" "StandardCAN";
BA_DEF_DEF_ "DoIPLogicalAddress" "";
BA_DEF_DEF_ "GenMsgRequestable" 1;
BA_DEF_DEF_ "CANFD_BRS" "1";
BA_ "BusType" "CAN FD";
BA_ "ProtocolType" "CAN FD";
BA_ "DBName" "CAN4";
BA_ "CAN_CAN_Gateway" BU_ FUSION 0;
BA_ "CANFD_CANFD_Gateway" BU_ FUSION 0;
BA_ "CAN_CANFD_Gateway" BU_ FUSION 0;
BA_ "CAN_CAN_Gateway" BU_ ZONE_RR 0;
BA_ "CANFD_CANFD_Gateway" BU_ ZONE_RR 0;
BA_ "CAN_CANFD_Gateway" BU_ ZONE_RR 0;
BA_ "CANFD_LIN_Gateway" BU_ ZONE_RR 0;
BA_ "GenMsgCycleTime" BO_ 513 5000;
BA_ "VFrameFormat" BO_ 513 14;
BA_ "GenMsgCycleTime" BO_ 514 5000;
BA_ "VFrameFormat" BO_ 514 14;
BA_ "VFrameFormat" BO_ 515 14;
BA_ "VFrameFormat" BO_ 2364605392 1;
BA_ "GenMsgNrOfRepetition" BO_ 2566803180 1;
BA_ "VFrameFormat" BO_ 2566803180 1;
BA_ "GenMsgSendType" BO_ 2566803180 5;
BA_ "GenMsgNrOfRepetition" BO_ 517 1;
BA_ "GenMsgSendType" BO_ 517 5;
BA_ "VFrameFormat" BO_ 517 14;
BA_ "GenMsgNrOfRepetition" BO_ 518 1;
BA_ "GenMsgSendType" BO_ 518 5;
BA_ "VFrameFormat" BO_ 518 14;
BA_ "GenMsgCycleTime" BO_ 522 50;
BA_ "VFrameFormat" BO_ 522 14;
BA_ "GenMsgCycleTime" BO_ 2364604880 10;
BA_ "VFrameFormat" BO_ 2364604880 1;
BA_ "GenMsgNrOfRepetition" BO_ 521 1;
BA_ "GenMsgSendType" BO_ 521 5;
BA_ "VFrameFormat" BO_ 521 14;
BA_ "GenMsgNrOfRepetition" BO_ 2583568724 1;
BA_ "VFrameFormat" BO_ 2583568724 1;
BA_ "GenMsgSendType" BO_ 2583568724 5;
BA_ "VFrameFormat" BO_ 2566831883 1;
BA_ "GenMsgCycleTime" BO_ 2565866479 200;
BA_ "VFrameFormat" BO_ 2565866479 1;
BA_ "GenMsgCycleTime" BO_ 2000 0;
BA_ "GenMsgSendType" BO_ 2000 3;
BA_ "DoIPLogicalAddress" BO_ 2000 "0xEFFF";
BA_ "GenMsgCycleTime" BO_ 1764 0;
BA_ "GenMsgSendType" BO_ 1764 3;
BA_ "VFrameFormat" BO_ 1764 14;
BA_ "DoIPLogicalAddress" BO_ 1764 "0x06E4";
BA_ "GenMsgCycleTime" BO_ 1636 0;
BA_ "GenMsgSendType" BO_ 1636 3;
BA_ "VFrameFormat" BO_ 1636 14;
BA_ "DoIPLogicalAddress" BO_ 1636 "0x06E4";
BA_ "GenMsgCycleTime" BO_ 1668 0;
BA_ "GenMsgSendType" BO_ 1668 3;
BA_ "VFrameFormat" BO_ 1668 14;
BA_ "DoIPLogicalAddress" BO_ 1668 "0x0684";
BA_ "GenMsgCycleTime" BO_ 1540 0;
BA_ "GenMsgSendType" BO_ 1540 3;
BA_ "VFrameFormat" BO_ 1540 14;
BA_ "DoIPLogicalAddress" BO_ 1540 "0x0684";
BA_ "GenMsgNrOfRepetition" BO_ 528 1;
BA_ "GenMsgSendType" BO_ 528 5;
BA_ "VFrameFormat" BO_ 528 14;
BA_ "GenMsgCycleTime" BO_ 1280 0;
BA_ "GenMsgSendType" BO_ 1280 3;
BA_ "GenMsgCycleTime" BO_ 1284 0;
BA_ "GenMsgSendType" BO_ 1284 3;
BA_ "GenMsgCycleTime" BO_ 1362 0;
BA_ "GenMsgSendType" BO_ 1362 3;
BA_ "GenSigRoutingTimeoutValue_String" SG_ 515 ParkBrakeSW "0x3";
BA_ "GenSigRoutingTimeoutValue" SG_ 515 ParkBrakeSW 3;
BA_ "GenSigInvalidValue" SG_ 2364605392 EACSpdDemand 20001;
BA_ "GenSigStartValue" SG_ 2364605392 EACSpdDemand 10000;
BA_ "GenSigInvalidValue" SG_ 2364605392 FDC_EHPS_SpdDemand_Cmd 20000;
BA_ "GenSigSendType" SG_ 2566803180 ZRR_BCM_AllDoor_Sta 3;
BA_ "GenSigSendType" SG_ 517 ZFR_BCM_Seatbelt_Sta 3;
BA_ "GenSigRoutingTimeoutValue_String" SG_ 517 ZFR_BCM_Brake_Sta "0x0";
BA_ "GenSigSendType" SG_ 517 ZFR_BCM_Brake_Sta 3;
BA_ "GenSigRoutingTimeoutValue_String" SG_ 517 ZFR_BCM_DVRSignalR_Sta "0x0";
BA_ "GenSigSendType" SG_ 517 ZFR_BCM_DVRSignalR_Sta 3;
BA_ "GenSigRoutingTimeoutValue_String" SG_ 517 ZFR_BCM_DVRSignalL_Sta "0x0";
BA_ "GenSigSendType" SG_ 517 ZFR_BCM_DVRSignalL_Sta 3;
BA_ "GenSigRoutingTimeoutValue_String" SG_ 517 ZFR_BCM_TurnBuzzer_Sta "0x0";
BA_ "GenSigSendType" SG_ 517 ZFR_BCM_TurnBuzzer_Sta 3;
BA_ "GenSigRoutingTimeoutValue_String" SG_ 517 ZFR_BCM_RBSDY_Sta "0x0";
BA_ "GenSigSendType" SG_ 517 ZFR_BCM_RBSDY_Sta 3;
BA_ "GenSigRoutingTimeoutValue_String" SG_ 517 ZFR_BCM_LBSDY_Sta "0x0";
BA_ "GenSigSendType" SG_ 517 ZFR_BCM_LBSDY_Sta 3;
BA_ "GenSigRoutingTimeoutValue_String" SG_ 517 ZFR_BCM_RBSDR_Sta "0x0";
BA_ "GenSigSendType" SG_ 517 ZFR_BCM_RBSDR_Sta 3;
BA_ "GenSigRoutingTimeoutValue_String" SG_ 517 ZFR_BCM_LBSDR_Sta "0x0";
BA_ "GenSigSendType" SG_ 517 ZFR_BCM_LBSDR_Sta 3;
BA_ "GenSigSendType" SG_ 517 ZFR_BCM_RFogLp_SW_Sta 3;
BA_ "GenSigRoutingTimeoutValue_String" SG_ 517 ZFR_BCM_Washer_Sta "0x0";
BA_ "GenSigSendType" SG_ 517 ZFR_BCM_Washer_Sta 3;
BA_ "GenSigSendType" SG_ 517 ZFR_BCM_WiperAS_Sta 3;
BA_ "GenSigRoutingTimeoutValue_String" SG_ 517 ZFR_BCM_WiperL_Sta "0x0";
BA_ "GenSigSendType" SG_ 517 ZFR_BCM_WiperL_Sta 3;
BA_ "GenSigRoutingTimeoutValue_String" SG_ 517 ZFR_BCM_WiperH_Sta "0x0";
BA_ "GenSigSendType" SG_ 517 ZFR_BCM_WiperH_Sta 3;
BA_ "GenSigRoutingTimeoutValue_String" SG_ 517 ZFR_BCM_DVRMidDoor_Sta "0x0";
BA_ "GenSigSendType" SG_ 517 ZFR_BCM_DVRMidDoor_Sta 3;
BA_ "GenSigRoutingTimeoutValue_String" SG_ 517 ZFR_BCM_RFTurnLp_Sta "0x0";
BA_ "GenSigSendType" SG_ 517 ZFR_BCM_RFTurnLp_Sta 3;
BA_ "GenSigRoutingTimeoutValue_String" SG_ 517 ZFR_BCM_LFTurnLp_Sta "0x0";
BA_ "GenSigSendType" SG_ 517 ZFR_BCM_LFTurnLp_Sta 3;
BA_ "GenSigRoutingTimeoutValue_String" SG_ 517 ZFR_BCM_RDRL_Sta "0x0";
BA_ "GenSigSendType" SG_ 517 ZFR_BCM_RDRL_Sta 3;
BA_ "GenSigRoutingTimeoutValue_String" SG_ 517 ZFR_BCM_LDRL_Sta "0x0";
BA_ "GenSigSendType" SG_ 517 ZFR_BCM_LDRL_Sta 3;
BA_ "GenSigRoutingTimeoutValue_String" SG_ 517 ZFR_BCM_PLamp_Sta "0x0";
BA_ "GenSigSendType" SG_ 517 ZFR_BCM_PLamp_Sta 3;
BA_ "GenSigRoutingTimeoutValue_String" SG_ 517 ZFR_BCM_HBeam_Sta "0x0";
BA_ "GenSigSendType" SG_ 517 ZFR_BCM_HBeam_Sta 3;
BA_ "GenSigRoutingTimeoutValue_String" SG_ 517 ZFR_BCM_LBeam_Sta "0x0";
BA_ "GenSigSendType" SG_ 517 ZFR_BCM_LBeam_Sta 3;
BA_ "GenSigSendType" SG_ 517 ZFR_BCM_LightSensorV_Sta 3;
BA_ "GenSigSendType" SG_ 517 ZFR_BCM_HBeamSW_Sta 3;
BA_ "GenSigSendType" SG_ 517 ZFR_BCM_AutoLightSW_Sta 3;
BA_ "GenSigSendType" SG_ 517 ZFR_BCM_PosLpSW_Sta 3;
BA_ "GenSigSendType" SG_ 517 ZFR_BCM_HeadLpSW_Sta 3;
BA_ "GenSigSendType" SG_ 517 ZFR_BCM_WiperHSW_Sta 3;
BA_ "GenSigSendType" SG_ 517 ZFR_BCM_WiperLSW_Sta 3;
BA_ "GenSigSendType" SG_ 517 ZFR_BCM_WasherSW_Sta 3;
BA_ "GenSigRoutingTimeoutValue_String" SG_ 517 ZFR_BCM_HornSW_Sta "0x0";
BA_ "GenSigSendType" SG_ 517 ZFR_BCM_HornSW_Sta 3;
BA_ "GenSigInvalidValue" SG_ 517 ZFR_BCM_RFTurnLpC_Sta 255;
BA_ "GenSigStartValue" SG_ 517 ZFR_BCM_RFTurnLpC_Sta 255;
BA_ "GenSigRoutingTimeoutValue_String" SG_ 517 ZFR_BCM_RFTurnLpC_Sta "0xFF";
BA_ "GenSigRoutingTimeoutValue" SG_ 517 ZFR_BCM_RFTurnLpC_Sta 255;
BA_ "GenSigSendType" SG_ 517 ZFR_BCM_RFTurnLpC_Sta 3;
BA_ "GenSigInvalidValue" SG_ 517 ZFR_BCM_LFTurnLpC_Sta 255;
BA_ "GenSigStartValue" SG_ 517 ZFR_BCM_LFTurnLpC_Sta 255;
BA_ "GenSigRoutingTimeoutValue_String" SG_ 517 ZFR_BCM_LFTurnLpC_Sta "0xFF";
BA_ "GenSigRoutingTimeoutValue" SG_ 517 ZFR_BCM_LFTurnLpC_Sta 255;
BA_ "GenSigSendType" SG_ 517 ZFR_BCM_LFTurnLpC_Sta 3;
BA_ "GenSigInvalidValue" SG_ 517 ZFR_BCM_BSD_Dimmer_Sta 127;
BA_ "GenSigRoutingTimeoutValue_String" SG_ 517 ZFR_BCM_BSD_Dimmer_Sta "0x7F";
BA_ "GenSigRoutingTimeoutValue" SG_ 517 ZFR_BCM_BSD_Dimmer_Sta 127;
BA_ "GenSigSendType" SG_ 517 ZFR_BCM_BSD_Dimmer_Sta 3;
BA_ "GenSigInvalidValue" SG_ 517 ZFR_BCM_BacklightDuty_Sta 127;
BA_ "GenSigRoutingTimeoutValue_String" SG_ 517 ZFR_BCM_BacklightDuty_Sta "0x7F";
BA_ "GenSigRoutingTimeoutValue" SG_ 517 ZFR_BCM_BacklightDuty_Sta 127;
BA_ "GenSigRoutingTimeoutValue_String" SG_ 517 AirPressureFC2 "0xFB";
BA_ "GenSigRoutingTimeoutValue" SG_ 517 AirPressureFC2 251;
BA_ "GenSigSendType" SG_ 517 ZFR_BCM_DVRSignalReverse_Sta 3;
BA_ "GenSigRoutingTimeoutValue_String" SG_ 518 ZRR_BCM_EmSV_Sta "0x0";
BA_ "GenSigSendType" SG_ 518 ZRR_BCM_EmSV_Sta 3;
BA_ "GenSigRoutingTimeoutValue_String" SG_ 518 ZRR_BCM_MDoorAP_Sta "0x0";
BA_ "GenSigSendType" SG_ 518 ZRR_BCM_MDoorAP_Sta 3;
BA_ "GenSigRoutingTimeoutValue_String" SG_ 518 ZRR_BCM_FDoorAP_Sta "0x0";
BA_ "GenSigSendType" SG_ 518 ZRR_BCM_FDoorAP_Sta 3;
BA_ "GenSigRoutingTimeoutValue_String" SG_ 518 ZRR_BCM_MDCloseSV_Sta "0x0";
BA_ "GenSigSendType" SG_ 518 ZRR_BCM_MDCloseSV_Sta 3;
BA_ "GenSigRoutingTimeoutValue_String" SG_ 518 ZRR_BCM_MDOpenSV_Sta "0x0";
BA_ "GenSigSendType" SG_ 518 ZRR_BCM_MDOpenSV_Sta 3;
BA_ "GenSigSendType" SG_ 518 ZRR_BCM_FDCloseSV_Sta 3;
BA_ "GenSigRoutingTimeoutValue_String" SG_ 518 ZRR_BCM_FDOpenSV_Sta "0x0";
BA_ "GenSigSendType" SG_ 518 ZRR_BCM_FDOpenSV_Sta 3;
BA_ "GenSigRoutingTimeoutValue_String" SG_ 518 ZRR_BCM_ReverseBuz_Sta "0x0";
BA_ "GenSigSendType" SG_ 518 ZRR_BCM_ReverseBuz_Sta 3;
BA_ "GenSigRoutingTimeoutValue_String" SG_ 518 ZRR_BCM_ReverseLp_Sta "0x0";
BA_ "GenSigSendType" SG_ 518 ZRR_BCM_ReverseLp_Sta 3;
BA_ "GenSigRoutingTimeoutValue_String" SG_ 518 ZRR_BCM_PLamp_Sta "0x0";
BA_ "GenSigSendType" SG_ 518 ZRR_BCM_PLamp_Sta 3;
BA_ "GenSigRoutingTimeoutValue_String" SG_ 518 ZRR_BCM_BrakeLp_Sta "0x0";
BA_ "GenSigSendType" SG_ 518 ZRR_BCM_BrakeLp_Sta 3;
BA_ "GenSigSendType" SG_ 518 ZRR_BCM_RFLamp_Sta 3;
BA_ "GenSigRoutingTimeoutValue_String" SG_ 518 ZRR_BCM_TurnBuzzer_Sta "0x0";
BA_ "GenSigSendType" SG_ 518 ZRR_BCM_TurnBuzzer_Sta 3;
BA_ "GenSigRoutingTimeoutValue_String" SG_ 518 ZRR_BCM_RRTurnLpC_Sta "0xFF";
BA_ "GenSigRoutingTimeoutValue" SG_ 518 ZRR_BCM_RRTurnLpC_Sta 255;
BA_ "GenSigSendType" SG_ 518 ZRR_BCM_RRTurnLpC_Sta 3;
BA_ "GenSigRoutingTimeoutValue_String" SG_ 518 ZRR_BCM_LRTurnLpC_Sta "0xFF";
BA_ "GenSigRoutingTimeoutValue" SG_ 518 ZRR_BCM_LRTurnLpC_Sta 255;
BA_ "GenSigSendType" SG_ 518 ZRR_BCM_LRTurnLpC_Sta 3;
BA_ "GenSigRoutingTimeoutValue_String" SG_ 518 ZRR_BCM_RRTurnLp_Sta "0x0";
BA_ "GenSigSendType" SG_ 518 ZRR_BCM_RRTurnLp_Sta 3;
BA_ "GenSigSendType" SG_ 518 ZRR_BCM_LRTurnLp_Sta 3;
BA_ "GenSigRoutingTimeoutValue_String" SG_ 518 ZRR_BCM_CallingSW_Sta "0x0";
BA_ "GenSigSendType" SG_ 518 ZRR_BCM_CallingSW_Sta 3;
BA_ "GenSigSendType" SG_ 518 ZRR_BCM_STOPSW2_Sta 3;
BA_ "GenSigRoutingTimeoutValue_String" SG_ 518 ZRR_BCM_STOPSW_Sta "0x0";
BA_ "GenSigSendType" SG_ 518 ZRR_BCM_STOPSW_Sta 3;
BA_ "GenSigRoutingTimeoutValue_String" SG_ 518 ZRR_BCM_SLTLp_Sta "0x0";
BA_ "GenSigSendType" SG_ 518 ZRR_BCM_SLTLp_Sta 3;
BA_ "GenSigRoutingTimeoutValue_String" SG_ 518 ZRR_BCM_SRTLp_Sta "0x0";
BA_ "GenSigSendType" SG_ 518 ZRR_BCM_SRTLp_Sta 3;
BA_ "GenSigRoutingTimeoutValue_String" SG_ 518 ZRR_BCM_SMKR_Sta "0x0";
BA_ "GenSigSendType" SG_ 518 ZRR_BCM_SMKR_Sta 3;
BA_ "GenSigRoutingTimeoutValue_String" SG_ 518 ZRR_BCM_SMKL_Sta "0x0";
BA_ "GenSigSendType" SG_ 518 ZRR_BCM_SMKL_Sta 3;
BA_ "GenSigRoutingTimeoutValue_String" SG_ 518 ZRR_BCM_RoomLpAmb_Sta "0x0";
BA_ "GenSigSendType" SG_ 518 ZRR_BCM_RoomLpAmb_Sta 3;
BA_ "GenSigRoutingTimeoutValue_String" SG_ 518 ZRR_BCM_StopLight_Sta "0x0";
BA_ "GenSigSendType" SG_ 518 ZRR_BCM_StopLight_Sta 3;
BA_ "GenSigRoutingTimeoutValue_String" SG_ 518 AirPressureRC1 "0xFB";
BA_ "GenSigRoutingTimeoutValue" SG_ 518 AirPressureRC1 251;
BA_ "GenSigRoutingTimeoutValue_String" SG_ 522 EAC_ErrLv_Sta "0x5";
BA_ "GenSigRoutingTimeoutValue" SG_ 522 EAC_ErrLv_Sta 5;
BA_ "GenSigRoutingTimeoutValue_String" SG_ 522 PDU_SelfChk_Sta "0x3";
BA_ "GenSigRoutingTimeoutValue" SG_ 522 PDU_SelfChk_Sta 3;
BA_ "GenSigRoutingTimeoutValue_String" SG_ 522 EHPS_ErrLv_Sta "0x5";
BA_ "GenSigRoutingTimeoutValue" SG_ 522 EHPS_ErrLv_Sta 5;
BA_ "GenSigRoutingTimeoutValue_String" SG_ 522 DCDC_ErrLv_Sta "0x5";
BA_ "GenSigRoutingTimeoutValue" SG_ 522 DCDC_ErrLv_Sta 5;
BA_ "GenSigRoutingTimeoutValue_String" SG_ 2364604880 ACHVPwrOnOffReq "0x0";
BA_ "GenSigRoutingTimeoutValue_String" SG_ 2364604880 VCU_DCDCEACEHPSRlyEn_cmd "0x3";
BA_ "GenSigRoutingTimeoutValue" SG_ 2364604880 VCU_DCDCEACEHPSRlyEn_cmd 3;
BA_ "GenSigRoutingTimeoutValue_String" SG_ 2364604880 VCU_DeFogTMSRlyEn_cmd "0x3";
BA_ "GenSigRoutingTimeoutValue" SG_ 2364604880 VCU_DeFogTMSRlyEn_cmd 3;
BA_ "GenSigRoutingTimeoutValue_String" SG_ 2364604880 MCUHVPwrOnOffReq "0x0";
BA_ "GenSigSendType" SG_ 521 FDC_BCM_EmSV_Cmd 3;
BA_ "GenSigSendType" SG_ 521 FDC_BCM_MDCloseSV_Cmd 3;
BA_ "GenSigSendType" SG_ 521 FDC_BCM_MDOpenSV_Cmd 3;
BA_ "GenSigSendType" SG_ 521 FDC_BCM_FDCloseSV_Cmd 3;
BA_ "GenSigSendType" SG_ 521 FDC_BCM_FDOpenSV_Cmd 3;
BA_ "GenSigSendType" SG_ 521 FDC_BCM_OutDoorOpenSW_Sta 3;
BA_ "GenSigRoutingTimeoutValue_String" SG_ 521 FDC_BCM_EmExitSW_Sta "0x0";
BA_ "GenSigSendType" SG_ 521 FDC_BCM_EmExitSW_Sta 3;
BA_ "GenSigRoutingTimeoutValue_String" SG_ 521 FDC_BCM_InnerBuzzer_Cmd "0x0";
BA_ "GenSigSendType" SG_ 521 FDC_BCM_InnerBuzzer_Cmd 3;
BA_ "GenSigSendType" SG_ 521 FDC_BCM_InnerBuzzerMode_Sta 3;
BA_ "GenSigRoutingTimeoutValue_String" SG_ 521 FDC_BCM_CallBell_Cmd "0x0";
BA_ "GenSigSendType" SG_ 521 FDC_BCM_CallBell_Cmd 3;
BA_ "GenSigRoutingTimeoutValue_String" SG_ 521 FDC_BCM_InnerCallBell_Cmd "0x0";
BA_ "GenSigSendType" SG_ 521 FDC_BCM_InnerCallBell_Cmd 3;
BA_ "GenSigSendType" SG_ 521 FDC_BCM_STOPBALL_Cmd 3;
BA_ "GenSigRoutingTimeoutValue_String" SG_ 521 FDC_BCM_TurnLpPattern_Sta "0x0";
BA_ "GenSigSendType" SG_ 521 FDC_BCM_TurnLpPattern_Sta 3;
BA_ "GenSigSendType" SG_ 521 FDC_BCM_RFLamp_Cmd 3;
BA_ "GenSigRoutingTimeoutValue_String" SG_ 521 FDC_BCM_Brake_Cmd "0x0";
BA_ "GenSigSendType" SG_ 521 FDC_BCM_Brake_Cmd 3;
BA_ "GenSigSendType" SG_ 521 FDC_BCM_SLTLp_Cmd 3;
BA_ "GenSigSendType" SG_ 521 FDC_BCM_SRTLp_Cmd 3;
BA_ "GenSigSendType" SG_ 521 FDC_BCM_SMKR_Cmd 3;
BA_ "GenSigSendType" SG_ 521 FDC_BCM_SMKL_Cmd 3;
BA_ "GenSigRoutingTimeoutValue_String" SG_ 521 FDC_BCM_RoomLpAmb_Cmd "0x0";
BA_ "GenSigSendType" SG_ 521 FDC_BCM_RoomLpAmb_Cmd 3;
BA_ "GenSigSendType" SG_ 521 FDC_BCM_Stop_IND_Cmd 3;
BA_ "GenSigRoutingTimeoutValue_String" SG_ 521 FDC_BCM_BSD_Buzzer_Cmd "0x0";
BA_ "GenSigSendType" SG_ 521 FDC_BCM_BSD_Buzzer_Cmd 3;
BA_ "GenSigSendType" SG_ 521 FDC_BCM_RBSDY_Cmd 3;
BA_ "GenSigSendType" SG_ 521 FDC_BCM_RBSDR_Cmd 3;
BA_ "GenSigSendType" SG_ 521 FDC_BCM_LBSDY_Cmd 3;
BA_ "GenSigSendType" SG_ 521 FDC_BCM_LBSDR_Cmd 3;
BA_ "GenSigRoutingTimeoutValue_String" SG_ 521 FDC_BCM_Washer_Cmd "0x0";
BA_ "GenSigSendType" SG_ 521 FDC_BCM_Washer_Cmd 3;
BA_ "GenSigRoutingTimeoutValue_String" SG_ 521 FDC_BCM_WiperL_Cmd "0x0";
BA_ "GenSigSendType" SG_ 521 FDC_BCM_WiperL_Cmd 3;
BA_ "GenSigRoutingTimeoutValue_String" SG_ 521 FDC_BCM_WiperH_Cmd "0x0";
BA_ "GenSigSendType" SG_ 521 FDC_BCM_WiperH_Cmd 3;
BA_ "GenSigRoutingTimeoutValue_String" SG_ 521 FDC_BCM_RGear_Sta "0x0";
BA_ "GenSigSendType" SG_ 521 FDC_BCM_RGear_Sta 3;
BA_ "GenSigRoutingTimeoutValue_String" SG_ 521 FDC_BCM_RDoor_Sta "0x0";
BA_ "GenSigSendType" SG_ 521 FDC_BCM_RDoor_Sta 3;
BA_ "GenSigSendType" SG_ 521 FDC_BCM_FDoor_Sta 3;
BA_ "GenSigSendType" SG_ 521 FDC_BCM_MDoor_Sta 3;
BA_ "GenSigSendType" SG_ 521 FDC_BCM_RDRL_Cmd 3;
BA_ "GenSigSendType" SG_ 521 FDC_BCM_LDRL_Cmd 3;
BA_ "GenSigSendType" SG_ 521 FDC_BCM_PLamp_Cmd 3;
BA_ "GenSigSendType" SG_ 521 FDC_BCM_HBeam_Cmd 3;
BA_ "GenSigSendType" SG_ 521 FDC_BCM_LBeam_Cmd 3;
BA_ "GenSigRoutingTimeoutValue_String" SG_ 521 VCUKeyStatus "0x3";
BA_ "GenSigRoutingTimeoutValue" SG_ 521 VCUKeyStatus 3;
BA_ "GenSigInvalidValue" SG_ 2583568724 IVI_Second_Sta 60;
BA_ "GenSigSendType" SG_ 2583568724 IVI_Second_Sta 3;
BA_ "GenSigInvalidValue" SG_ 2583568724 IVI_Minute_Sta 60;
BA_ "GenSigSendType" SG_ 2583568724 IVI_Minute_Sta 3;
BA_ "GenSigSendType" SG_ 2583568724 IVI_Hour_Sta 3;
BA_ "GenSigSendType" SG_ 2583568724 IVI_Day_Sta 3;
BA_ "GenSigSendType" SG_ 2583568724 IVI_Month_Sta 3;
BA_ "GenSigSendType" SG_ 2583568724 IVI_Year_Sta 3;
BA_ "GenSigRoutingTimeoutValue_String" SG_ 2566831883 FASpeed "0xFB00";
BA_ "GenSigRoutingTimeoutValue" SG_ 2566831883 FASpeed 64256;
BA_ "GenSigRoutingTimeoutValue_String" SG_ 2565866479 VCUIRCSta "0x0";
BA_ "GenSigRoutingTimeoutValue_String" SG_ 2565866479 VCUIGNSta "0x0";
BA_ "GenSigInvalidValue" SG_ 2565866479 SysPowerMode 15;
BA_ "GenSigSendType" SG_ 2000 DiagFuncReqFT 3;
BA_ "GenSigSendType" SG_ 1764 DiagPhysReqToZONE_RR 3;
BA_ "GenSigSendType" SG_ 1636 DiagRespFromZONE_RR 3;
BA_ "GenSigSendType" SG_ 1668 DiagPhysReqToZONE_FR 3;
BA_ "GenSigSendType" SG_ 1540 DiagRespFromZONE_FR 3;
BA_ "GenSigInvalidValue" SG_ 528 FDC_THCM_CoolFanReq_Cmd 255;
BA_ "GenSigSendType" SG_ 528 FDC_THCM_CoolFanReq_Cmd 3;
BA_ "GenSigSendType" SG_ 1280 NM_FUSION_Node_ID 7;
BA_ "GenSigSendType" SG_ 1280 NM_FUSION_ERROR_State 7;
BA_ "GenSigSendType" SG_ 1280 NM_FUSION_Active_WU 7;
BA_ "GenSigSendType" SG_ 1280 NM_FUSION_CSB 7;
BA_ "GenSigSendType" SG_ 1280 NM_FUSION_PNI 7;
BA_ "GenSigSendType" SG_ 1280 NM_FUSION_Rpt_Msg_Req 7;
BA_ "GenSigSendType" SG_ 1284 NM_ZONE_FR_Node_ID 7;
BA_ "GenSigSendType" SG_ 1284 NM_ZONE_FR_ERROR 7;
BA_ "GenSigSendType" SG_ 1284 NM_ZONE_FR_Active_WU 7;
BA_ "GenSigSendType" SG_ 1284 NM_ZONE_FR_CSB 7;
BA_ "GenSigSendType" SG_ 1284 NM_ZONE_FR_PNI 7;
BA_ "GenSigSendType" SG_ 1284 NM_ZONE_FR_Rpt_Msg_Req 7;
BA_ "GenSigSendType" SG_ 1362 NM_ZONE_RR_Node_ID 7;
BA_ "GenSigSendType" SG_ 1362 NM_ZONE_RR_ERROR 7;
BA_ "GenSigSendType" SG_ 1362 NM_ZONE_RR_Active_WU 7;
BA_ "GenSigSendType" SG_ 1362 NM_ZONE_RR_CSB 7;
BA_ "GenSigSendType" SG_ 1362 NM_ZONE_RR_PNI 7;
BA_ "GenSigSendType" SG_ 1362 NM_ZONE_RR_Rpt_Msg_Req 7;
VAL_ 513 ZFR_CHASSIS_LiningWearFL_Sta 1 "Need to Replace Lining" 0 "Not Need to Replace Lining";
VAL_ 513 ZFR_CHASSIS_LiningWearFR_Sta 1 "Need to Replace Lining" 0 "Not Need to Replace Lining";
VAL_ 514 ZRR_CHASSIS_LiningWearRR_Sta 1 "Need to Replace Lining" 0 "Not Need to Replace Lining";
VAL_ 514 ZRR_CHASSIS_LiningWearRL_Sta 1 "Need to Replace Lining" 0 "Not Need to Replace Lining";
VAL_ 515 ParkBrakeSW 3 "Not available" 2 "Error" 1 "Parking brake set" 0 "Parking brake not set";
VAL_ 2364605392 FDC_CHA_EACEnDemand_Cmd 170 "shut down" 85 "start";
VAL_ 2364605392 DCDCEnDemand 170 "shut down" 85 "start";
VAL_ 2364605392 FDC_EHPS_EnDemand_Cmd 170 "Shut down" 85 "Start";
VAL_ 2566803180 ZRR_BCM_AllDoor_Sta 2 "All doors closed" 1 "Closing last door" 0 "At least 1 door is open";
VAL_ 517 ZFR_BCM_Seatbelt_Sta 1 "fasten" 0 "Unfasten";
VAL_ 517 ZFR_BCM_Brake_Sta 1 "ON" 0 "OFF";
VAL_ 517 ZFR_BCM_DVRSignalR_Sta 1 "ON" 0 "OFF";
VAL_ 517 ZFR_BCM_DVRSignalL_Sta 1 "ON" 0 "OFF";
VAL_ 517 ZFR_BCM_TurnBuzzer_Sta 1 "ON" 0 "OFF";
VAL_ 517 ZFR_BCM_RBSDY_Sta 1 "ON" 0 "OFF";
VAL_ 517 ZFR_BCM_LBSDY_Sta 1 "ON" 0 "OFF";
VAL_ 517 ZFR_BCM_RBSDR_Sta 1 "ON" 0 "OFF";
VAL_ 517 ZFR_BCM_LBSDR_Sta 1 "ON" 0 "OFF";
VAL_ 517 ZFR_BCM_RFogLp_SW_Sta 1 "ON" 0 "OFF";
VAL_ 517 ZFR_BCM_Washer_Sta 1 "ON" 0 "OFF";
VAL_ 517 ZFR_BCM_WiperAS_Sta 1 "ON" 0 "OFF";
VAL_ 517 ZFR_BCM_WiperL_Sta 1 "ON" 0 "OFF";
VAL_ 517 ZFR_BCM_WiperH_Sta 1 "ON" 0 "OFF";
VAL_ 517 ZFR_BCM_DVRMidDoor_Sta 1 "ON" 0 "OFF";
VAL_ 517 ZFR_BCM_RFTurnLp_Sta 1 "ON" 0 "OFF";
VAL_ 517 ZFR_BCM_LFTurnLp_Sta 1 "ON" 0 "OFF";
VAL_ 517 ZFR_BCM_RDRL_Sta 1 "ON" 0 "OFF";
VAL_ 517 ZFR_BCM_LDRL_Sta 1 "ON" 0 "OFF";
VAL_ 517 ZFR_BCM_PLamp_Sta 1 "ON" 0 "OFF";
VAL_ 517 ZFR_BCM_HBeam_Sta 1 "ON" 0 "OFF";
VAL_ 517 ZFR_BCM_LBeam_Sta 1 "ON" 0 "OFF";
VAL_ 517 ZFR_BCM_HBeamSW_Sta 1 "ON" 0 "OFF";
VAL_ 517 ZFR_BCM_AutoLightSW_Sta 1 "ON" 0 "OFF";
VAL_ 517 ZFR_BCM_PosLpSW_Sta 1 "ON" 0 "OFF";
VAL_ 517 ZFR_BCM_HeadLpSW_Sta 1 "ON" 0 "OFF";
VAL_ 517 ZFR_BCM_WiperHSW_Sta 1 "ON" 0 "OFF";
VAL_ 517 ZFR_BCM_WiperLSW_Sta 1 "ON" 0 "OFF";
VAL_ 517 ZFR_BCM_WasherSW_Sta 1 "ON" 0 "OFF";
VAL_ 517 ZFR_BCM_HornSW_Sta 1 "Press" 0 "Release";
VAL_ 517 ZFR_BCM_RFTurnLpC_Sta 255 "invaild";
VAL_ 517 ZFR_BCM_LFTurnLpC_Sta 255 "invaild";
VAL_ 517 ZFR_BCM_BSD_Dimmer_Sta 101 "~0x7F Invalid";
VAL_ 517 ZFR_BCM_BacklightDuty_Sta 101 "~0x7F Invalid";
VAL_ 517 AirPressureFC2 251 "Invalid Value";
VAL_ 517 ZFR_BCM_DVRSignalReverse_Sta 1 "ON" 0 "OFF";
VAL_ 518 ZRR_BCM_EmSV_Sta 1 "ON" 0 "OFF";
VAL_ 518 ZRR_BCM_MDoorAP_Sta 1 "ON" 0 "OFF";
VAL_ 518 ZRR_BCM_FDoorAP_Sta 1 "ON" 0 "OFF";
VAL_ 518 ZRR_BCM_MDCloseSV_Sta 1 "ON" 0 "OFF";
VAL_ 518 ZRR_BCM_MDOpenSV_Sta 1 "ON" 0 "OFF";
VAL_ 518 ZRR_BCM_FDCloseSV_Sta 1 "ON" 0 "OFF";
VAL_ 518 ZRR_BCM_FDOpenSV_Sta 1 "ON" 0 "OFF";
VAL_ 518 ZRR_BCM_ReverseBuz_Sta 1 "ON" 0 "OFF";
VAL_ 518 ZRR_BCM_ReverseLp_Sta 1 "ON" 0 "OFF";
VAL_ 518 ZRR_BCM_PLamp_Sta 1 "ON" 0 "OFF";
VAL_ 518 ZRR_BCM_BrakeLp_Sta 1 "ON" 0 "OFF";
VAL_ 518 ZRR_BCM_RFLamp_Sta 1 "ON" 0 "OFF";
VAL_ 518 ZRR_BCM_TurnBuzzer_Sta 1 "ON" 0 "OFF";
VAL_ 518 ZRR_BCM_RRTurnLpC_Sta 255 "Invalid";
VAL_ 518 ZRR_BCM_LRTurnLpC_Sta 255 "Invalid";
VAL_ 518 ZRR_BCM_RRTurnLp_Sta 1 "ON" 0 "OFF";
VAL_ 518 ZRR_BCM_LRTurnLp_Sta 1 "ON" 0 "OFF";
VAL_ 518 ZRR_BCM_CallingSW_Sta 1 "ON" 0 "OFF";
VAL_ 518 ZRR_BCM_STOPSW2_Sta 1 "ON" 0 "OFF";
VAL_ 518 ZRR_BCM_STOPSW_Sta 1 "ON" 0 "OFF";
VAL_ 518 ZRR_BCM_SLTLp_Sta 1 "ON" 0 "OFF";
VAL_ 518 ZRR_BCM_SRTLp_Sta 1 "ON" 0 "OFF";
VAL_ 518 ZRR_BCM_SMKR_Sta 1 "ON" 0 "OFF";
VAL_ 518 ZRR_BCM_SMKL_Sta 1 "ON" 0 "OFF";
VAL_ 518 ZRR_BCM_RoomLpAmb_Sta 1 "ON" 0 "OFF";
VAL_ 518 ZRR_BCM_StopLight_Sta 1 "ON" 0 "OFF";
VAL_ 518 AirPressureRC1 251 "Invalid Value";
VAL_ 518 FDC_CHASSIS_VCUEACPress_Sta 1 "Open" 0 "Close";
VAL_ 518 ZRR_BCM_EmLight_Sta 1 "ON" 0 "OFF";
VAL_ 522 EAC_ErrLv_Sta 7 "Not available" 6 "Not available" 5 "Not available" 4 "Level4" 3 "Level3" 2 "Level2" 1 "Level1" 0 "No error";
VAL_ 522 PDU_DCDCEACEHPSHVLoop_Sta 3 "Precharge fault" 2 "Precharge Finish" 1 "Precharging" 0 "Open";
VAL_ 522 PDU_DCDCEACEHPSPreRly_Sta 3 "Closed Failure" 2 "Welded" 1 "Close" 0 "Open";
VAL_ 522 PDU_SelfChk_Sta 3 "Not available" 2 "Reserved" 1 "Fault" 0 "No fault";
VAL_ 522 PDU_MCUPreRly_Sta 3 "Closd Failure" 2 "Welded" 1 "Close" 0 "Open";
VAL_ 522 PDU_MCUPosRly_Sta 3 "Closd Failure" 2 "Welded" 1 "Close" 0 "Open";
VAL_ 522 PDU_MCUHVLoop_Sta 3 "Prechage Fault" 2 "Precharg Finish" 1 "Precharging" 0 "Open";
VAL_ 522 PDU_ACRly_Sta 3 "Closd Failure" 2 "Welded" 1 "Close" 0 "Open";
VAL_ 522 PDU_DeFogTMSRly_Sta 3 "Closd Failure" 2 "Welded" 1 "Close" 0 "Open";
VAL_ 522 PDU_DCDCEACEHPSRly_Sta 3 "Closd Failure" 2 "Welded" 1 "Close" 0 "Open";
VAL_ 522 PDU_HVIL_Sta 3 "EAC_interlock signal is Wrong" 2 "EHPS_interlock signal is Wrong" 1 "PDU_interlock signal is Wrong" 0 "Normal";
VAL_ 522 EHPS_ErrLv_Sta 7 "Not available" 6 "Not available" 5 "Not available" 4 "Level4" 3 "Level3" 2 "Level2" 1 "Level1" 0 "No error";
VAL_ 522 EHPS_En_Sta 3 "FAULT" 2 "RUN" 1 "Ready" 0 "INITIAL";
VAL_ 522 EAC_En_Sta 3 "FAULT" 2 "RUN" 1 "Ready" 0 "INITIAL";
VAL_ 522 DCDC_ErrLv_Sta 7 "Not available" 6 "Not available" 5 "Not available" 4 "Level4" 3 "Level3" 2 "Level2" 1 "Level1" 0 "No error";
VAL_ 522 DCDC_En_Sta 3 "FAULT" 2 "RUN" 1 "Ready" 0 "INITIAL";
VAL_ 2364604880 ACHVPwrOnOffReq 3 "Not available" 2 "Disable Demand" 1 "Enable Demand" 0 "Not available";
VAL_ 2364604880 VCU_DCDCEACEHPSRlyEn_cmd 3 "Not available" 2 "Disable demand" 1 "Enable demand" 0 "Not available";
VAL_ 2364604880 VCU_DeFogTMSRlyEn_cmd 3 "Not available" 2 "Disable demand" 1 "Enable demand" 0 "Not available";
VAL_ 2364604880 MCUHVPwrOnOffReq 3 "Not available" 2 "Disable Demand" 1 "Enable Demand" 0 "Not available";
VAL_ 521 FDC_BCM_EmSV_Cmd 1 "Door_Can_not_Open" 0 "Door_Can_Open";
VAL_ 521 FDC_BCM_MDCloseSV_Cmd 1 "ON" 0 "OFF";
VAL_ 521 FDC_BCM_MDOpenSV_Cmd 1 "ON" 0 "OFF";
VAL_ 521 FDC_BCM_FDCloseSV_Cmd 1 "ON" 0 "OFF";
VAL_ 521 FDC_BCM_FDOpenSV_Cmd 1 "ON" 0 "OFF";
VAL_ 521 FDC_BCM_OutDoorOpenSW_Sta 2 "ClosePos" 1 "OpenPos" 0 "OFF";
VAL_ 521 FDC_BCM_EmExitSW_Sta 1 "ON" 0 "OFF";
VAL_ 521 FDC_BCM_InnerBuzzer_Cmd 1 "ON" 0 "OFF";
VAL_ 521 FDC_BCM_InnerBuzzerMode_Sta 5 "VCU Warning" 4 "TA Buzzer" 3 "DoorOpen Warning" 2 "Emergency Exit Open" 1 "Fire Disaster" 0 "OFF";
VAL_ 521 FDC_BCM_CallBell_Cmd 1 "ON" 0 "OFF";
VAL_ 521 FDC_BCM_InnerCallBell_Cmd 1 "ON" 0 "OFF";
VAL_ 521 FDC_BCM_STOPBALL_Cmd 1 "ON" 0 "OFF";
VAL_ 521 FDC_BCM_TurnLpPattern_Sta 3 "Turn Right" 2 "Turn Left" 1 "Hazard" 0 "No Request";
VAL_ 521 FDC_BCM_RFLamp_Cmd 1 "ON" 0 "OFF";
VAL_ 521 FDC_BCM_Brake_Cmd 1 "Brake" 0 "Not At Brake";
VAL_ 521 FDC_BCM_SLTLp_Cmd 1 "ON" 0 "OFF";
VAL_ 521 FDC_BCM_SRTLp_Cmd 1 "ON" 0 "OFF";
VAL_ 521 FDC_BCM_SMKR_Cmd 1 "ON" 0 "OFF";
VAL_ 521 FDC_BCM_SMKL_Cmd 1 "ON" 0 "OFF";
VAL_ 521 FDC_BCM_RoomLpAmb_Cmd 1 "ON" 0 "OFF";
VAL_ 521 FDC_BCM_Stop_IND_Cmd 1 "ON" 0 "OFF";
VAL_ 521 FDC_BCM_BSD_Buzzer_Cmd 1 "ON" 0 "OFF";
VAL_ 521 FDC_BCM_RBSDY_Cmd 1 "ON" 0 "OFF";
VAL_ 521 FDC_BCM_RBSDR_Cmd 1 "ON" 0 "OFF";
VAL_ 521 FDC_BCM_LBSDY_Cmd 1 "ON" 0 "OFF";
VAL_ 521 FDC_BCM_LBSDR_Cmd 1 "ON" 0 "OFF";
VAL_ 521 FDC_BCM_Washer_Cmd 1 "ON" 0 "OFF";
VAL_ 521 FDC_BCM_WiperL_Cmd 1 "ON" 0 "OFF";
VAL_ 521 FDC_BCM_WiperH_Cmd 1 "ON" 0 "OFF";
VAL_ 521 FDC_BCM_RGear_Sta 1 "R Gear" 0 "Not R Gear";
VAL_ 521 FDC_BCM_RDoor_Sta 1 "Open" 0 "Close";
VAL_ 521 FDC_BCM_FDoor_Sta 1 "ON" 0 "OFF";
VAL_ 521 FDC_BCM_MDoor_Sta 1 "ON" 0 "OFF";
VAL_ 521 FDC_BCM_RDRL_Cmd 1 "ON" 0 "OFF";
VAL_ 521 FDC_BCM_LDRL_Cmd 1 "ON" 0 "OFF";
VAL_ 521 FDC_BCM_PLamp_Cmd 1 "ON" 0 "OFF";
VAL_ 521 FDC_BCM_HBeam_Cmd 1 "ON" 0 "OFF";
VAL_ 521 FDC_BCM_LBeam_Cmd 1 "ON" 0 "OFF";
VAL_ 521 FDC_BCM_LTurnLp_Cmd 1 "ON" 0 "OFF";
VAL_ 521 FDC_BCM_RTurnLp_Cmd 1 "ON" 0 "OFF";
VAL_ 521 FDC_BCM_DVRSignalR_Cmd 1 "ON" 0 "OFF";
VAL_ 521 FDC_BCM_DVRSignalL_Cmd 1 "ON" 0 "OFF";
VAL_ 521 VCUKeyStatus 3 "reserved" 2 "START" 1 "ON" 0 "OFF";
VAL_ 2583568724 IVI_Second_Sta 60 "Invalid Value";
VAL_ 2583568724 IVI_Minute_Sta 60 "Invalid Value";
VAL_ 2583568724 IVI_Month_Sta 13 "Invalid Value";
VAL_ 2566831883 FASpeed 64256 "Invalid Value";
VAL_ 2565866479 VCUIRCSta 1 "ON" 0 "OFF";
VAL_ 2565866479 VCUIGNSta 1 "ON" 0 "OFF";
VAL_ 2565866479 SysPowerMode 8 "LV Batt Charge" 7 "Charge" 6 "Afterrun" 5 "sleep" 4 "Power down" 3 "Drive" 2 "Power up" 1 "stand by" 0 "self checking";
VAL_ 528 FDC_BCM_RRoomLp_Cmd 101 "~0x7F no used";
VAL_ 528 FDC_BCM_FRoomLp_Cmd 101 "~0x7F no used";
VAL_ 528 FDC_BCM_MRoomLp_Cmd 101 "~0x7F no used";
VAL_ 1280 NM_FUSION_ERROR_State 8 "BUS OFF_L2" 4 "BUS OFF_L1" 2 "ERROR PASSIVE" 1 "ERROR ACTIVE" 0 "Inactive";
VAL_ 1280 NM_FUSION_Active_WU 1 "Node has woken up the network (active Wakeup)" 0 "Node has not woken up the network (passive wakeup)";
VAL_ 1280 NM_FUSION_CSB 1 "Start of synchronized shutdown is requested by main coordinator" 0 "Start of synchronized shutdown is not requested by main coordinator";
VAL_ 1280 NM_FUSION_PNI 1 "NM PDU contains Partial Network request information" 0 "NM PDU contains no Partial Network request information";
VAL_ 1280 NM_FUSION_Rpt_Msg_Req 1 "Repeat Message State requested" 0 "Repeat Message State not requested";
VAL_ 1284 NM_ZONE_FR_ERROR 8 "BUS OFF_L2" 4 "BUS OFF_L1" 2 "ERROR PASSIVE" 1 "ERROR ACTIVE" 0 "Inactive";
VAL_ 1284 NM_ZONE_FR_Active_WU 1 "Node has woken up the network (active Wakeup)" 0 "Node has not woken up the network (passive wakeup)";
VAL_ 1284 NM_ZONE_FR_CSB 1 "Start of synchronized shutdown is requested by main coordinator" 0 "Start of synchronized shutdown is not requested by main coordinator";
VAL_ 1284 NM_ZONE_FR_PNI 1 "NM PDU contains Partial Network request information" 0 "NM PDU contains no Partial Network request information";
VAL_ 1284 NM_ZONE_FR_Rpt_Msg_Req 1 "Repeat Message State requested" 0 "Repeat Message State not requested";
VAL_ 1362 NM_ZONE_RR_ERROR 8 "BUS OFF_L2" 4 "BUS OFF_L1" 2 "ERROR PASSIVE" 1 "ERROR ACTIVE" 0 "Inactive";
VAL_ 1362 NM_ZONE_RR_Active_WU 1 "Node has woken up the network (active Wakeup)" 0 "Node has not woken up the network (passive wakeup)";
VAL_ 1362 NM_ZONE_RR_CSB 1 "Start of synchronized shutdown is requested by main coordinator" 0 "Start of synchronized shutdown is not requested by main coordinator";
VAL_ 1362 NM_ZONE_RR_PNI 1 "NM PDU contains Partial Network request information" 0 "NM PDU contains no Partial Network request information";
VAL_ 1362 NM_ZONE_RR_Rpt_Msg_Req 1 "Repeat Message State requested" 0 "Repeat Message State not requested";
